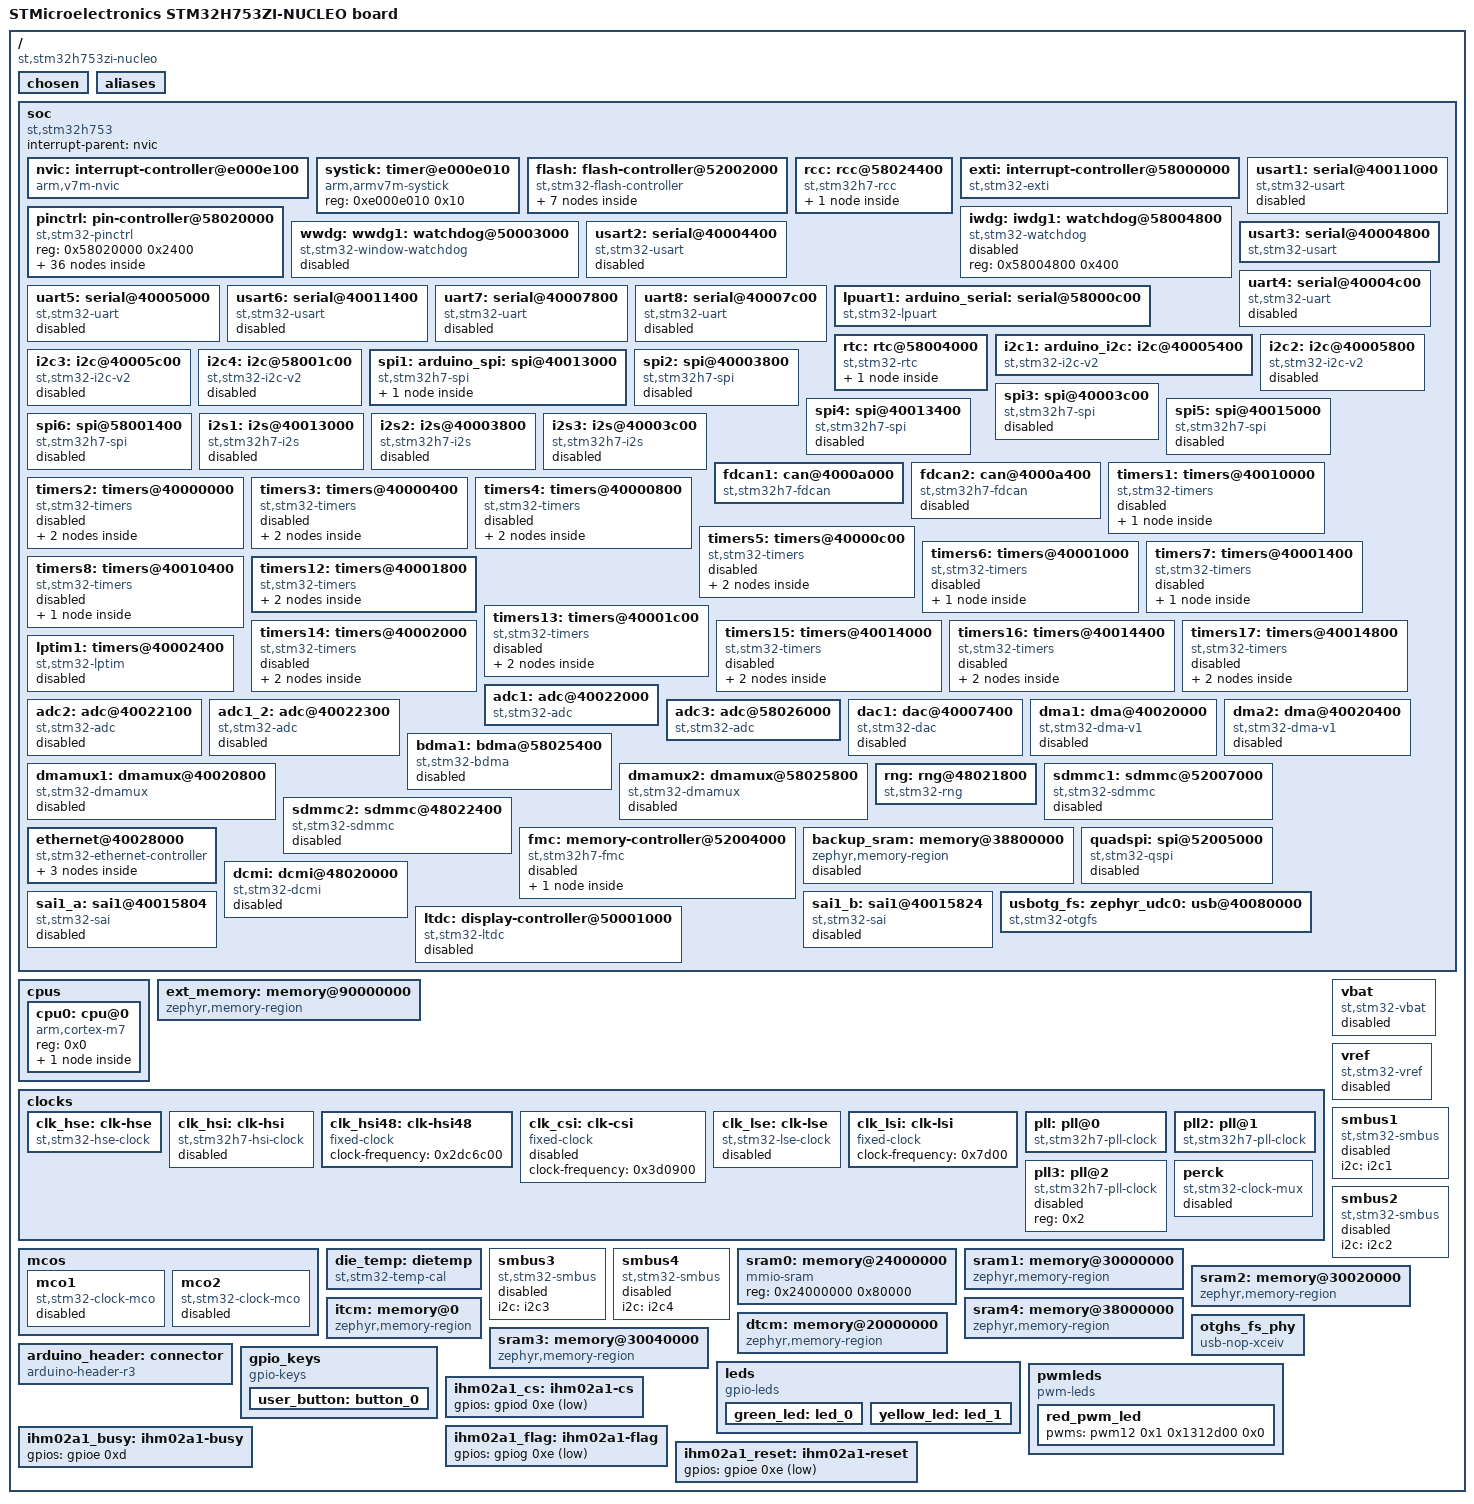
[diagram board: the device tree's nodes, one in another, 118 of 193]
/dts-v1/;

/* node '/' defined in zephyr/dts/common/skeleton.dtsi:9 */
/ {
	#address-cells = < 0x1 >;                              /* in zephyr/dts/common/skeleton.dtsi:10 */
	#size-cells = < 0x1 >;                                 /* in zephyr/dts/common/skeleton.dtsi:11 */
	model = "STMicroelectronics STM32H753ZI-NUCLEO board"; /* in zephyr/boards/st/nucleo_h753zi/nucleo_h753zi.dts:14 */
	compatible = "st,stm32h753zi-nucleo";                  /* in zephyr/boards/st/nucleo_h753zi/nucleo_h753zi.dts:15 */

	/* node '/chosen' defined in zephyr/dts/common/skeleton.dtsi:12 */
	chosen {
		zephyr,entropy = &rng;                    /* in zephyr/dts/arm/st/h7/stm32h7.dtsi:28 */
		zephyr,flash-controller = &flash;         /* in zephyr/dts/arm/st/h7/stm32h7.dtsi:29 */
		zephyr,shell-uart = &usart3;              /* in zephyr/boards/st/nucleo_h753zi/nucleo_h753zi.dts:19 */
		zephyr,sram = &sram0;                     /* in zephyr/boards/st/nucleo_h753zi/nucleo_h753zi.dts:20 */
		zephyr,flash = &flash0;                   /* in zephyr/boards/st/nucleo_h753zi/nucleo_h753zi.dts:21 */
		zephyr,dtcm = &dtcm;                      /* in zephyr/boards/st/nucleo_h753zi/nucleo_h753zi.dts:22 */
		zephyr,code-partition = &slot0_partition; /* in zephyr/boards/st/nucleo_h753zi/nucleo_h753zi.dts:23 */
		zephyr,canbus = &fdcan1;                  /* in zephyr/boards/st/nucleo_h753zi/nucleo_h753zi.dts:24 */
		zephyr,console = &usart3;                 /* in ../apps/stm32h753zi_stepper/boards/shields/x_nucleo_ihm02a1/x_nucleo_ihm02a1.overlay:13 */
	};

	/* node '/aliases' defined in zephyr/dts/common/skeleton.dtsi:13 */
	aliases {
		die-temp0 = &die_temp;   /* in zephyr/boards/st/nucleo_h753zi/nucleo_h753zi.dts:60 */
		led0 = &green_led;       /* in zephyr/boards/st/nucleo_h753zi/nucleo_h753zi.dts:61 */
		led1 = &yellow_led;      /* in zephyr/boards/st/nucleo_h753zi/nucleo_h753zi.dts:62 */
		pwm-led0 = &red_pwm_led; /* in zephyr/boards/st/nucleo_h753zi/nucleo_h753zi.dts:63 */
		sw0 = &user_button;      /* in zephyr/boards/st/nucleo_h753zi/nucleo_h753zi.dts:64 */
		volt-sensor1 = &vbat;    /* in zephyr/boards/st/nucleo_h753zi/nucleo_h753zi.dts:65 */
	};

	/* node '/soc' defined in zephyr/dts/arm/armv7-m.dtsi:6 */
	soc {
		#address-cells = < 0x1 >;     /* in zephyr/dts/arm/armv7-m.dtsi:7 */
		#size-cells = < 0x1 >;        /* in zephyr/dts/arm/armv7-m.dtsi:8 */
		interrupt-parent = < &nvic >; /* in zephyr/dts/arm/armv7-m.dtsi:10 */
		ranges;                       /* in zephyr/dts/arm/armv7-m.dtsi:11 */
		compatible = "st,stm32h753",
		             "st,stm32h7",
		             "simple-bus";    /* in zephyr/dts/arm/st/h7/stm32h753.dtsi:11 */

		/* node '/soc/interrupt-controller@e000e100' defined in zephyr/dts/arm/armv7-m.dtsi:13 */
		nvic: interrupt-controller@e000e100 {
			#address-cells = < 0x1 >;            /* in zephyr/dts/arm/armv7-m.dtsi:14 */
			compatible = "arm,v7m-nvic";         /* in zephyr/dts/arm/armv7-m.dtsi:15 */
			reg = < 0xe000e100 0xc00 >;          /* in zephyr/dts/arm/armv7-m.dtsi:16 */
			interrupt-controller;                /* in zephyr/dts/arm/armv7-m.dtsi:17 */
			#interrupt-cells = < 0x2 >;          /* in zephyr/dts/arm/armv7-m.dtsi:18 */
			arm,num-irq-priority-bits = < 0x4 >; /* in zephyr/dts/arm/st/h7/stm32h7.dtsi:1196 */
			phandle = < 0x1 >;                   /* in zephyr/dts/arm/armv7-m.dtsi:10 */
		};

		/* node '/soc/timer@e000e010' defined in zephyr/dts/arm/armv7-m.dtsi:21 */
		systick: timer@e000e010 {
			compatible = "arm,armv7m-systick"; /* in zephyr/dts/arm/armv7-m.dtsi:22 */
			reg = < 0xe000e010 0x10 >;         /* in zephyr/dts/arm/armv7-m.dtsi:23 */
		};

		/* node '/soc/flash-controller@52002000' defined in zephyr/dts/arm/st/h7/stm32h7.dtsi:145 */
		flash: flash-controller@52002000 {
			compatible = "st,stm32-flash-controller",
			             "st,stm32h7-flash-controller"; /* in zephyr/dts/arm/st/h7/stm32h7.dtsi:146 */
			reg = < 0x52002000 0x400 >;                 /* in zephyr/dts/arm/st/h7/stm32h7.dtsi:147 */
			interrupts = < 0x4 0x0 >;                   /* in zephyr/dts/arm/st/h7/stm32h7.dtsi:148 */
			#address-cells = < 0x1 >;                   /* in zephyr/dts/arm/st/h7/stm32h7.dtsi:150 */
			#size-cells = < 0x1 >;                      /* in zephyr/dts/arm/st/h7/stm32h7.dtsi:151 */

			/* node '/soc/flash-controller@52002000/flash@8000000' defined in zephyr/dts/arm/st/h7/stm32h742.dtsi:15 */
			flash0: flash@8000000 {
				compatible = "st,stm32-nv-flash",
				             "soc-nv-flash";      /* in zephyr/dts/arm/st/h7/stm32h742.dtsi:16 */
				write-block-size = < 0x20 >;      /* in zephyr/dts/arm/st/h7/stm32h742.dtsi:17 */
				erase-block-size = < 0x20000 >;   /* in zephyr/dts/arm/st/h7/stm32h742.dtsi:18 */
				max-erase-time = < 0xfa0 >;       /* in zephyr/dts/arm/st/h7/stm32h742.dtsi:20 */
				reg = < 0x8000000 0x200000 >;     /* in zephyr/dts/arm/st/h7/stm32h753Xi.dtsi:14 */

				/* node '/soc/flash-controller@52002000/flash@8000000/partitions' defined in zephyr/boards/st/nucleo_h753zi/nucleo_h753zi.dts:231 */
				partitions {
					compatible = "fixed-partitions"; /* in zephyr/boards/st/nucleo_h753zi/nucleo_h753zi.dts:232 */
					#address-cells = < 0x1 >;        /* in zephyr/boards/st/nucleo_h753zi/nucleo_h753zi.dts:233 */
					#size-cells = < 0x1 >;           /* in zephyr/boards/st/nucleo_h753zi/nucleo_h753zi.dts:234 */

					/* node '/soc/flash-controller@52002000/flash@8000000/partitions/partition@0' defined in zephyr/boards/st/nucleo_h753zi/nucleo_h753zi.dts:237 */
					boot_partition: partition@0 {
						label = "mcuboot";     /* in zephyr/boards/st/nucleo_h753zi/nucleo_h753zi.dts:238 */
						reg = < 0x0 0x20000 >; /* in zephyr/boards/st/nucleo_h753zi/nucleo_h753zi.dts:239 */
						read-only;             /* in zephyr/boards/st/nucleo_h753zi/nucleo_h753zi.dts:240 */
					};

					/* node '/soc/flash-controller@52002000/flash@8000000/partitions/partition@20000' defined in zephyr/boards/st/nucleo_h753zi/nucleo_h753zi.dts:244 */
					storage_partition: partition@20000 {
						label = "storage";         /* in zephyr/boards/st/nucleo_h753zi/nucleo_h753zi.dts:245 */
						reg = < 0x20000 0x20000 >; /* in zephyr/boards/st/nucleo_h753zi/nucleo_h753zi.dts:246 */
					};

					/* node '/soc/flash-controller@52002000/flash@8000000/partitions/partition@40000' defined in zephyr/boards/st/nucleo_h753zi/nucleo_h753zi.dts:250 */
					slot0_partition: partition@40000 {
						label = "image-0";         /* in zephyr/boards/st/nucleo_h753zi/nucleo_h753zi.dts:251 */
						reg = < 0x40000 0x40000 >; /* in zephyr/boards/st/nucleo_h753zi/nucleo_h753zi.dts:252 */
					};

					/* node '/soc/flash-controller@52002000/flash@8000000/partitions/partition@80000' defined in zephyr/boards/st/nucleo_h753zi/nucleo_h753zi.dts:256 */
					slot1_partition: partition@80000 {
						label = "image-1";         /* in zephyr/boards/st/nucleo_h753zi/nucleo_h753zi.dts:257 */
						reg = < 0x80000 0x40000 >; /* in zephyr/boards/st/nucleo_h753zi/nucleo_h753zi.dts:258 */
					};

					/* node '/soc/flash-controller@52002000/flash@8000000/partitions/partition@c0000' defined in zephyr/boards/st/nucleo_h753zi/nucleo_h753zi.dts:262 */
					scratch_partition: partition@c0000 {
						label = "image-scratch";   /* in zephyr/boards/st/nucleo_h753zi/nucleo_h753zi.dts:263 */
						reg = < 0xc0000 0x20000 >; /* in zephyr/boards/st/nucleo_h753zi/nucleo_h753zi.dts:264 */
					};
				};
			};
		};

		/* node '/soc/rcc@58024400' defined in zephyr/dts/arm/st/h7/stm32h7.dtsi:154 */
		rcc: rcc@58024400 {
			compatible = "st,stm32h7-rcc";    /* in zephyr/dts/arm/st/h7/stm32h7.dtsi:155 */
			#clock-cells = < 0x2 >;           /* in zephyr/dts/arm/st/h7/stm32h7.dtsi:156 */
			reg = < 0x58024400 0x400 >;       /* in zephyr/dts/arm/st/h7/stm32h7.dtsi:157 */
			clocks = < &pll >;                /* in zephyr/boards/st/nucleo_h753zi/nucleo_h753zi.dts:104 */
			clock-frequency = < 0x1c9c3800 >; /* in zephyr/boards/st/nucleo_h753zi/nucleo_h753zi.dts:105 */
			d1cpre = < 0x1 >;                 /* in zephyr/boards/st/nucleo_h753zi/nucleo_h753zi.dts:106 */
			hpre = < 0x2 >;                   /* in zephyr/boards/st/nucleo_h753zi/nucleo_h753zi.dts:107 */
			d1ppre = < 0x2 >;                 /* in zephyr/boards/st/nucleo_h753zi/nucleo_h753zi.dts:108 */
			d2ppre1 = < 0x2 >;                /* in zephyr/boards/st/nucleo_h753zi/nucleo_h753zi.dts:109 */
			d2ppre2 = < 0x2 >;                /* in zephyr/boards/st/nucleo_h753zi/nucleo_h753zi.dts:110 */
			d3ppre = < 0x2 >;                 /* in zephyr/boards/st/nucleo_h753zi/nucleo_h753zi.dts:111 */
			phandle = < 0x3 >;                /* in zephyr/dts/arm/st/h7/stm32h7.dtsi:171 */

			/* node '/soc/rcc@58024400/reset-controller' defined in zephyr/dts/arm/st/h7/stm32h7.dtsi:159 */
			rctl: reset-controller {
				compatible = "st,stm32-rcc-rctl"; /* in zephyr/dts/arm/st/h7/stm32h7.dtsi:160 */
				#reset-cells = < 0x1 >;           /* in zephyr/dts/arm/st/h7/stm32h7.dtsi:161 */
				phandle = < 0x4 >;                /* in zephyr/dts/arm/st/h7/stm32h7.dtsi:294 */
			};
		};

		/* node '/soc/interrupt-controller@58000000' defined in zephyr/dts/arm/st/h7/stm32h7.dtsi:165 */
		exti: interrupt-controller@58000000 {
			compatible = "st,stm32-exti";  /* in zephyr/dts/arm/st/h7/stm32h7.dtsi:166 */
			interrupt-controller;          /* in zephyr/dts/arm/st/h7/stm32h7.dtsi:167 */
			#interrupt-cells = < 0x1 >;    /* in zephyr/dts/arm/st/h7/stm32h7.dtsi:168 */
			#address-cells = < 0x1 >;      /* in zephyr/dts/arm/st/h7/stm32h7.dtsi:169 */
			reg = < 0x58000000 0x400 >;    /* in zephyr/dts/arm/st/h7/stm32h7.dtsi:170 */
			clocks = < &rcc 0xf4 0x2 >;    /* in zephyr/dts/arm/st/h7/stm32h7.dtsi:171 */
			num-lines = < 0x60 >;          /* in zephyr/dts/arm/st/h7/stm32h7.dtsi:172 */
			interrupts = < 0x6 0x0 >,
			             < 0x7 0x0 >,
			             < 0x8 0x0 >,
			             < 0x9 0x0 >,
			             < 0xa 0x0 >,
			             < 0x17 0x0 >,
			             < 0x28 0x0 >;     /* in zephyr/dts/arm/st/h7/stm32h7.dtsi:173 */
			interrupt-names = "line0",
			                  "line1",
			                  "line2",
			                  "line3",
			                  "line4",
			                  "line5-9",
			                  "line10-15"; /* in zephyr/dts/arm/st/h7/stm32h7.dtsi:175 */
			line-ranges = < 0x0 0x1 >,
			              < 0x1 0x1 >,
			              < 0x2 0x1 >,
			              < 0x3 0x1 >,
			              < 0x4 0x1 >,
			              < 0x5 0x5 >,
			              < 0xa 0x6 >;     /* in zephyr/dts/arm/st/h7/stm32h7.dtsi:177 */
		};

		/* node '/soc/pin-controller@58020000' defined in zephyr/dts/arm/st/h7/stm32h7.dtsi:181 */
		pinctrl: pin-controller@58020000 {
			compatible = "st,stm32-pinctrl"; /* in zephyr/dts/arm/st/h7/stm32h7.dtsi:182 */
			#address-cells = < 0x1 >;        /* in zephyr/dts/arm/st/h7/stm32h7.dtsi:183 */
			#size-cells = < 0x1 >;           /* in zephyr/dts/arm/st/h7/stm32h7.dtsi:184 */
			reg = < 0x58020000 0x2400 >;     /* in zephyr/dts/arm/st/h7/stm32h7.dtsi:185 */

			/* node '/soc/pin-controller@58020000/gpio@58020000' defined in zephyr/dts/arm/st/h7/stm32h7.dtsi:187 */
			gpioa: gpio@58020000 {
				compatible = "st,stm32-gpio"; /* in zephyr/dts/arm/st/h7/stm32h7.dtsi:188 */
				gpio-controller;              /* in zephyr/dts/arm/st/h7/stm32h7.dtsi:189 */
				#gpio-cells = < 0x2 >;        /* in zephyr/dts/arm/st/h7/stm32h7.dtsi:190 */
				reg = < 0x58020000 0x400 >;   /* in zephyr/dts/arm/st/h7/stm32h7.dtsi:191 */
				clocks = < &rcc 0xe0 0x1 >;   /* in zephyr/dts/arm/st/h7/stm32h7.dtsi:192 */
				phandle = < 0x29 >;           /* in zephyr/boards/st/nucleo_h753zi/arduino_r3_connector.dtsi:13 */
			};

			/* node '/soc/pin-controller@58020000/gpio@58020400' defined in zephyr/dts/arm/st/h7/stm32h7.dtsi:195 */
			gpiob: gpio@58020400 {
				compatible = "st,stm32-gpio"; /* in zephyr/dts/arm/st/h7/stm32h7.dtsi:196 */
				gpio-controller;              /* in zephyr/dts/arm/st/h7/stm32h7.dtsi:197 */
				#gpio-cells = < 0x2 >;        /* in zephyr/dts/arm/st/h7/stm32h7.dtsi:198 */
				reg = < 0x58020400 0x400 >;   /* in zephyr/dts/arm/st/h7/stm32h7.dtsi:199 */
				clocks = < &rcc 0xe0 0x2 >;   /* in zephyr/dts/arm/st/h7/stm32h7.dtsi:200 */
				phandle = < 0x2b >;           /* in zephyr/boards/st/nucleo_h753zi/arduino_r3_connector.dtsi:13 */
			};

			/* node '/soc/pin-controller@58020000/gpio@58020800' defined in zephyr/dts/arm/st/h7/stm32h7.dtsi:203 */
			gpioc: gpio@58020800 {
				compatible = "st,stm32-gpio"; /* in zephyr/dts/arm/st/h7/stm32h7.dtsi:204 */
				gpio-controller;              /* in zephyr/dts/arm/st/h7/stm32h7.dtsi:205 */
				#gpio-cells = < 0x2 >;        /* in zephyr/dts/arm/st/h7/stm32h7.dtsi:206 */
				reg = < 0x58020800 0x400 >;   /* in zephyr/dts/arm/st/h7/stm32h7.dtsi:207 */
				clocks = < &rcc 0xe0 0x4 >;   /* in zephyr/dts/arm/st/h7/stm32h7.dtsi:208 */
				phandle = < 0x2a >;           /* in zephyr/boards/st/nucleo_h753zi/arduino_r3_connector.dtsi:13 */
			};

			/* node '/soc/pin-controller@58020000/gpio@58020C00' defined in zephyr/dts/arm/st/h7/stm32h7.dtsi:211 */
			gpiod: gpio@58020C00 {
				compatible = "st,stm32-gpio"; /* in zephyr/dts/arm/st/h7/stm32h7.dtsi:212 */
				gpio-controller;              /* in zephyr/dts/arm/st/h7/stm32h7.dtsi:213 */
				#gpio-cells = < 0x2 >;        /* in zephyr/dts/arm/st/h7/stm32h7.dtsi:214 */
				reg = < 0x58020c00 0x400 >;   /* in zephyr/dts/arm/st/h7/stm32h7.dtsi:215 */
				clocks = < &rcc 0xe0 0x8 >;   /* in zephyr/dts/arm/st/h7/stm32h7.dtsi:216 */
				phandle = < 0xe >;            /* in zephyr/boards/st/nucleo_h753zi/nucleo_h753zi.dts:227 */
			};

			/* node '/soc/pin-controller@58020000/gpio@58021000' defined in zephyr/dts/arm/st/h7/stm32h7.dtsi:219 */
			gpioe: gpio@58021000 {
				compatible = "st,stm32-gpio"; /* in zephyr/dts/arm/st/h7/stm32h7.dtsi:220 */
				gpio-controller;              /* in zephyr/dts/arm/st/h7/stm32h7.dtsi:221 */
				#gpio-cells = < 0x2 >;        /* in zephyr/dts/arm/st/h7/stm32h7.dtsi:222 */
				reg = < 0x58021000 0x400 >;   /* in zephyr/dts/arm/st/h7/stm32h7.dtsi:223 */
				clocks = < &rcc 0xe0 0x10 >;  /* in zephyr/dts/arm/st/h7/stm32h7.dtsi:224 */
				phandle = < 0x2e >;           /* in zephyr/boards/st/nucleo_h753zi/arduino_r3_connector.dtsi:13 */
			};

			/* node '/soc/pin-controller@58020000/gpio@58021400' defined in zephyr/dts/arm/st/h7/stm32h7.dtsi:227 */
			gpiof: gpio@58021400 {
				compatible = "st,stm32-gpio"; /* in zephyr/dts/arm/st/h7/stm32h7.dtsi:228 */
				gpio-controller;              /* in zephyr/dts/arm/st/h7/stm32h7.dtsi:229 */
				#gpio-cells = < 0x2 >;        /* in zephyr/dts/arm/st/h7/stm32h7.dtsi:230 */
				reg = < 0x58021400 0x400 >;   /* in zephyr/dts/arm/st/h7/stm32h7.dtsi:231 */
				clocks = < &rcc 0xe0 0x20 >;  /* in zephyr/dts/arm/st/h7/stm32h7.dtsi:232 */
				phandle = < 0x2c >;           /* in zephyr/boards/st/nucleo_h753zi/arduino_r3_connector.dtsi:13 */
			};

			/* node '/soc/pin-controller@58020000/gpio@58021800' defined in zephyr/dts/arm/st/h7/stm32h7.dtsi:235 */
			gpiog: gpio@58021800 {
				compatible = "st,stm32-gpio"; /* in zephyr/dts/arm/st/h7/stm32h7.dtsi:236 */
				gpio-controller;              /* in zephyr/dts/arm/st/h7/stm32h7.dtsi:237 */
				#gpio-cells = < 0x2 >;        /* in zephyr/dts/arm/st/h7/stm32h7.dtsi:238 */
				reg = < 0x58021800 0x400 >;   /* in zephyr/dts/arm/st/h7/stm32h7.dtsi:239 */
				clocks = < &rcc 0xe0 0x40 >;  /* in zephyr/dts/arm/st/h7/stm32h7.dtsi:240 */
				phandle = < 0x2d >;           /* in zephyr/boards/st/nucleo_h753zi/arduino_r3_connector.dtsi:13 */
			};

			/* node '/soc/pin-controller@58020000/gpio@58021C00' defined in zephyr/dts/arm/st/h7/stm32h7.dtsi:243 */
			gpioh: gpio@58021C00 {
				compatible = "st,stm32-gpio"; /* in zephyr/dts/arm/st/h7/stm32h7.dtsi:244 */
				gpio-controller;              /* in zephyr/dts/arm/st/h7/stm32h7.dtsi:245 */
				#gpio-cells = < 0x2 >;        /* in zephyr/dts/arm/st/h7/stm32h7.dtsi:246 */
				reg = < 0x58021c00 0x400 >;   /* in zephyr/dts/arm/st/h7/stm32h7.dtsi:247 */
				clocks = < &rcc 0xe0 0x80 >;  /* in zephyr/dts/arm/st/h7/stm32h7.dtsi:248 */
			};

			/* node '/soc/pin-controller@58020000/gpio@58022000' defined in zephyr/dts/arm/st/h7/stm32h7.dtsi:251 */
			gpioi: gpio@58022000 {
				compatible = "st,stm32-gpio"; /* in zephyr/dts/arm/st/h7/stm32h7.dtsi:252 */
				gpio-controller;              /* in zephyr/dts/arm/st/h7/stm32h7.dtsi:253 */
				#gpio-cells = < 0x2 >;        /* in zephyr/dts/arm/st/h7/stm32h7.dtsi:254 */
				reg = < 0x58022000 0x400 >;   /* in zephyr/dts/arm/st/h7/stm32h7.dtsi:255 */
				clocks = < &rcc 0xe0 0x100 >; /* in zephyr/dts/arm/st/h7/stm32h7.dtsi:256 */
			};

			/* node '/soc/pin-controller@58020000/gpio@58022400' defined in zephyr/dts/arm/st/h7/stm32h7.dtsi:259 */
			gpioj: gpio@58022400 {
				compatible = "st,stm32-gpio"; /* in zephyr/dts/arm/st/h7/stm32h7.dtsi:260 */
				gpio-controller;              /* in zephyr/dts/arm/st/h7/stm32h7.dtsi:261 */
				#gpio-cells = < 0x2 >;        /* in zephyr/dts/arm/st/h7/stm32h7.dtsi:262 */
				reg = < 0x58022400 0x400 >;   /* in zephyr/dts/arm/st/h7/stm32h7.dtsi:263 */
				clocks = < &rcc 0xe0 0x200 >; /* in zephyr/dts/arm/st/h7/stm32h7.dtsi:264 */
			};

			/* node '/soc/pin-controller@58020000/gpio@58022800' defined in zephyr/dts/arm/st/h7/stm32h7.dtsi:267 */
			gpiok: gpio@58022800 {
				compatible = "st,stm32-gpio"; /* in zephyr/dts/arm/st/h7/stm32h7.dtsi:268 */
				gpio-controller;              /* in zephyr/dts/arm/st/h7/stm32h7.dtsi:269 */
				#gpio-cells = < 0x2 >;        /* in zephyr/dts/arm/st/h7/stm32h7.dtsi:270 */
				reg = < 0x58022800 0x400 >;   /* in zephyr/dts/arm/st/h7/stm32h7.dtsi:271 */
				clocks = < &rcc 0xe0 0x400 >; /* in zephyr/dts/arm/st/h7/stm32h7.dtsi:272 */
			};

			/* node '/soc/pin-controller@58020000/adc1_inp15_pa3' defined in modules/hal/stm32/dts/st/h7/stm32h753zitx-pinctrl.dtsi:31 */
			adc1_inp15_pa3: adc1_inp15_pa3 {
				pinmux = < 0x70 >;  /* in modules/hal/stm32/dts/st/h7/stm32h753zitx-pinctrl.dtsi:32 */
				phandle = < 0x13 >; /* in zephyr/boards/st/nucleo_h753zi/nucleo_h753zi.dts:159 */
			};

			/* node '/soc/pin-controller@58020000/adc3_inp5_pf3' defined in modules/hal/stm32/dts/st/h7/stm32h753zitx-pinctrl.dtsi:211 */
			adc3_inp5_pf3: adc3_inp5_pf3 {
				pinmux = < 0xa70 >; /* in modules/hal/stm32/dts/st/h7/stm32h753zitx-pinctrl.dtsi:212 */
				phandle = < 0x14 >; /* in zephyr/boards/st/nucleo_h753zi/nucleo_h753zi.dts:167 */
			};

			/* node '/soc/pin-controller@58020000/eth_ref_clk_pa1' defined in modules/hal/stm32/dts/st/h7/stm32h753zitx-pinctrl.dtsi:1185 */
			eth_ref_clk_pa1: eth_ref_clk_pa1 {
				pinmux = < 0x2b >;             /* in modules/hal/stm32/dts/st/h7/stm32h753zitx-pinctrl.dtsi:1186 */
				slew-rate = "very-high-speed"; /* in modules/hal/stm32/dts/st/h7/stm32h753zitx-pinctrl.dtsi:1187 */
				phandle = < 0x17 >;            /* in zephyr/boards/st/nucleo_h753zi/nucleo_h753zi.dts:200 */
			};

			/* node '/soc/pin-controller@58020000/eth_mdio_pa2' defined in modules/hal/stm32/dts/st/h7/stm32h753zitx-pinctrl.dtsi:1195 */
			eth_mdio_pa2: eth_mdio_pa2 {
				pinmux = < 0x4b >;             /* in modules/hal/stm32/dts/st/h7/stm32h753zitx-pinctrl.dtsi:1196 */
				slew-rate = "very-high-speed"; /* in modules/hal/stm32/dts/st/h7/stm32h753zitx-pinctrl.dtsi:1197 */
				phandle = < 0x1d >;            /* in zephyr/boards/st/nucleo_h753zi/nucleo_h753zi.dts:214 */
			};

			/* node '/soc/pin-controller@58020000/eth_crs_dv_pa7' defined in modules/hal/stm32/dts/st/h7/stm32h753zitx-pinctrl.dtsi:1205 */
			eth_crs_dv_pa7: eth_crs_dv_pa7 {
				pinmux = < 0xeb >;             /* in modules/hal/stm32/dts/st/h7/stm32h753zitx-pinctrl.dtsi:1206 */
				slew-rate = "very-high-speed"; /* in modules/hal/stm32/dts/st/h7/stm32h753zitx-pinctrl.dtsi:1207 */
				phandle = < 0x18 >;            /* in zephyr/boards/st/nucleo_h753zi/nucleo_h753zi.dts:200 */
			};

			/* node '/soc/pin-controller@58020000/eth_txd1_pb13' defined in modules/hal/stm32/dts/st/h7/stm32h753zitx-pinctrl.dtsi:1250 */
			eth_txd1_pb13: eth_txd1_pb13 {
				pinmux = < 0x3ab >;            /* in modules/hal/stm32/dts/st/h7/stm32h753zitx-pinctrl.dtsi:1251 */
				slew-rate = "very-high-speed"; /* in modules/hal/stm32/dts/st/h7/stm32h753zitx-pinctrl.dtsi:1252 */
				phandle = < 0x1b >;            /* in zephyr/boards/st/nucleo_h753zi/nucleo_h753zi.dts:200 */
			};

			/* node '/soc/pin-controller@58020000/eth_mdc_pc1' defined in modules/hal/stm32/dts/st/h7/stm32h753zitx-pinctrl.dtsi:1255 */
			eth_mdc_pc1: eth_mdc_pc1 {
				pinmux = < 0x42b >;            /* in modules/hal/stm32/dts/st/h7/stm32h753zitx-pinctrl.dtsi:1256 */
				slew-rate = "very-high-speed"; /* in modules/hal/stm32/dts/st/h7/stm32h753zitx-pinctrl.dtsi:1257 */
				phandle = < 0x1e >;            /* in zephyr/boards/st/nucleo_h753zi/nucleo_h753zi.dts:214 */
			};

			/* node '/soc/pin-controller@58020000/eth_rxd0_pc4' defined in modules/hal/stm32/dts/st/h7/stm32h753zitx-pinctrl.dtsi:1270 */
			eth_rxd0_pc4: eth_rxd0_pc4 {
				pinmux = < 0x48b >;            /* in modules/hal/stm32/dts/st/h7/stm32h753zitx-pinctrl.dtsi:1271 */
				slew-rate = "very-high-speed"; /* in modules/hal/stm32/dts/st/h7/stm32h753zitx-pinctrl.dtsi:1272 */
				phandle = < 0x15 >;            /* in zephyr/boards/st/nucleo_h753zi/nucleo_h753zi.dts:200 */
			};

			/* node '/soc/pin-controller@58020000/eth_rxd1_pc5' defined in modules/hal/stm32/dts/st/h7/stm32h753zitx-pinctrl.dtsi:1275 */
			eth_rxd1_pc5: eth_rxd1_pc5 {
				pinmux = < 0x4ab >;            /* in modules/hal/stm32/dts/st/h7/stm32h753zitx-pinctrl.dtsi:1276 */
				slew-rate = "very-high-speed"; /* in modules/hal/stm32/dts/st/h7/stm32h753zitx-pinctrl.dtsi:1277 */
				phandle = < 0x16 >;            /* in zephyr/boards/st/nucleo_h753zi/nucleo_h753zi.dts:200 */
			};

			/* node '/soc/pin-controller@58020000/eth_tx_en_pg11' defined in modules/hal/stm32/dts/st/h7/stm32h753zitx-pinctrl.dtsi:1290 */
			eth_tx_en_pg11: eth_tx_en_pg11 {
				pinmux = < 0xd6b >;            /* in modules/hal/stm32/dts/st/h7/stm32h753zitx-pinctrl.dtsi:1291 */
				slew-rate = "very-high-speed"; /* in modules/hal/stm32/dts/st/h7/stm32h753zitx-pinctrl.dtsi:1292 */
				phandle = < 0x19 >;            /* in zephyr/boards/st/nucleo_h753zi/nucleo_h753zi.dts:200 */
			};

			/* node '/soc/pin-controller@58020000/eth_txd0_pg13' defined in modules/hal/stm32/dts/st/h7/stm32h753zitx-pinctrl.dtsi:1300 */
			eth_txd0_pg13: eth_txd0_pg13 {
				pinmux = < 0xdab >;            /* in modules/hal/stm32/dts/st/h7/stm32h753zitx-pinctrl.dtsi:1301 */
				slew-rate = "very-high-speed"; /* in modules/hal/stm32/dts/st/h7/stm32h753zitx-pinctrl.dtsi:1302 */
				phandle = < 0x1a >;            /* in zephyr/boards/st/nucleo_h753zi/nucleo_h753zi.dts:200 */
			};

			/* node '/soc/pin-controller@58020000/fdcan1_rx_pd0' defined in modules/hal/stm32/dts/st/h7/stm32h753zitx-pinctrl.dtsi:1320 */
			fdcan1_rx_pd0: fdcan1_rx_pd0 {
				pinmux = < 0x609 >; /* in modules/hal/stm32/dts/st/h7/stm32h753zitx-pinctrl.dtsi:1321 */
				phandle = < 0x10 >; /* in zephyr/boards/st/nucleo_h753zi/nucleo_h753zi.dts:185 */
			};

			/* node '/soc/pin-controller@58020000/fdcan1_tx_pd1' defined in modules/hal/stm32/dts/st/h7/stm32h753zitx-pinctrl.dtsi:1342 */
			fdcan1_tx_pd1: fdcan1_tx_pd1 {
				pinmux = < 0x629 >; /* in modules/hal/stm32/dts/st/h7/stm32h753zitx-pinctrl.dtsi:1343 */
				phandle = < 0x11 >; /* in zephyr/boards/st/nucleo_h753zi/nucleo_h753zi.dts:185 */
			};

			/* node '/soc/pin-controller@58020000/i2c1_scl_pb8' defined in modules/hal/stm32/dts/st/h7/stm32h753zitx-pinctrl.dtsi:1790 */
			i2c1_scl_pb8: i2c1_scl_pb8 {
				pinmux = < 0x304 >; /* in modules/hal/stm32/dts/st/h7/stm32h753zitx-pinctrl.dtsi:1791 */
				bias-pull-up;       /* in modules/hal/stm32/dts/st/h7/stm32h753zitx-pinctrl.dtsi:1792 */
				drive-open-drain;   /* in modules/hal/stm32/dts/st/h7/stm32h753zitx-pinctrl.dtsi:1793 */
				phandle = < 0x9 >;  /* in zephyr/boards/st/nucleo_h753zi/nucleo_h753zi.dts:141 */
			};

			/* node '/soc/pin-controller@58020000/i2c1_sda_pb9' defined in modules/hal/stm32/dts/st/h7/stm32h753zitx-pinctrl.dtsi:1846 */
			i2c1_sda_pb9: i2c1_sda_pb9 {
				pinmux = < 0x324 >; /* in modules/hal/stm32/dts/st/h7/stm32h753zitx-pinctrl.dtsi:1847 */
				bias-pull-up;       /* in modules/hal/stm32/dts/st/h7/stm32h753zitx-pinctrl.dtsi:1848 */
				drive-open-drain;   /* in modules/hal/stm32/dts/st/h7/stm32h753zitx-pinctrl.dtsi:1849 */
				phandle = < 0xa >;  /* in zephyr/boards/st/nucleo_h753zi/nucleo_h753zi.dts:141 */
			};

			/* node '/soc/pin-controller@58020000/spi1_miso_pa6' defined in modules/hal/stm32/dts/st/h7/stm32h753zitx-pinctrl.dtsi:2836 */
			spi1_miso_pa6: spi1_miso_pa6 {
				pinmux = < 0xc5 >; /* in modules/hal/stm32/dts/st/h7/stm32h753zitx-pinctrl.dtsi:2837 */
				bias-pull-down;    /* in modules/hal/stm32/dts/st/h7/stm32h753zitx-pinctrl.dtsi:2838 */
				phandle = < 0xc >; /* in zephyr/boards/st/nucleo_h753zi/nucleo_h753zi.dts:225 */
			};

			/* node '/soc/pin-controller@58020000/spi1_mosi_pb5' defined in modules/hal/stm32/dts/st/h7/stm32h753zitx-pinctrl.dtsi:2908 */
			spi1_mosi_pb5: spi1_mosi_pb5 {
				pinmux = < 0x2a5 >; /* in modules/hal/stm32/dts/st/h7/stm32h753zitx-pinctrl.dtsi:2909 */
				bias-pull-down;     /* in modules/hal/stm32/dts/st/h7/stm32h753zitx-pinctrl.dtsi:2910 */
				phandle = < 0xd >;  /* in zephyr/boards/st/nucleo_h753zi/nucleo_h753zi.dts:225 */
			};

			/* node '/soc/pin-controller@58020000/spi1_sck_pa5' defined in modules/hal/stm32/dts/st/h7/stm32h753zitx-pinctrl.dtsi:3067 */
			spi1_sck_pa5: spi1_sck_pa5 {
				pinmux = < 0xa5 >;             /* in modules/hal/stm32/dts/st/h7/stm32h753zitx-pinctrl.dtsi:3068 */
				bias-pull-down;                /* in modules/hal/stm32/dts/st/h7/stm32h753zitx-pinctrl.dtsi:3069 */
				slew-rate = "very-high-speed"; /* in modules/hal/stm32/dts/st/h7/stm32h753zitx-pinctrl.dtsi:3070 */
				phandle = < 0xb >;             /* in zephyr/boards/st/nucleo_h753zi/nucleo_h753zi.dts:225 */
			};

			/* node '/soc/pin-controller@58020000/tim12_ch1_pb14' defined in modules/hal/stm32/dts/st/h7/stm32h753zitx-pinctrl.dtsi:3331 */
			tim12_ch1_pb14: tim12_ch1_pb14 {
				pinmux = < 0x3c2 >; /* in modules/hal/stm32/dts/st/h7/stm32h753zitx-pinctrl.dtsi:3332 */
				phandle = < 0x12 >; /* in zephyr/boards/st/nucleo_h753zi/nucleo_h753zi.dts:153 */
			};

			/* node '/soc/pin-controller@58020000/lpuart1_rx_pb7' defined in modules/hal/stm32/dts/st/h7/stm32h753zitx-pinctrl.dtsi:3765 */
			lpuart1_rx_pb7: lpuart1_rx_pb7 {
				pinmux = < 0x2e8 >; /* in modules/hal/stm32/dts/st/h7/stm32h753zitx-pinctrl.dtsi:3766 */
				phandle = < 0x8 >;  /* in zephyr/boards/st/nucleo_h753zi/nucleo_h753zi.dts:115 */
			};

			/* node '/soc/pin-controller@58020000/usart3_rx_pd9' defined in modules/hal/stm32/dts/st/h7/stm32h753zitx-pinctrl.dtsi:3793 */
			usart3_rx_pd9: usart3_rx_pd9 {
				pinmux = < 0x727 >; /* in modules/hal/stm32/dts/st/h7/stm32h753zitx-pinctrl.dtsi:3794 */
				phandle = < 0x6 >;  /* in zephyr/boards/st/nucleo_h753zi/nucleo_h753zi.dts:122 */
			};

			/* node '/soc/pin-controller@58020000/lpuart1_tx_pb6' defined in modules/hal/stm32/dts/st/h7/stm32h753zitx-pinctrl.dtsi:3869 */
			lpuart1_tx_pb6: lpuart1_tx_pb6 {
				pinmux = < 0x2c8 >; /* in modules/hal/stm32/dts/st/h7/stm32h753zitx-pinctrl.dtsi:3870 */
				bias-pull-up;       /* in modules/hal/stm32/dts/st/h7/stm32h753zitx-pinctrl.dtsi:3871 */
				phandle = < 0x7 >;  /* in zephyr/boards/st/nucleo_h753zi/nucleo_h753zi.dts:115 */
			};

			/* node '/soc/pin-controller@58020000/usart3_tx_pd8' defined in modules/hal/stm32/dts/st/h7/stm32h753zitx-pinctrl.dtsi:3904 */
			usart3_tx_pd8: usart3_tx_pd8 {
				pinmux = < 0x707 >; /* in modules/hal/stm32/dts/st/h7/stm32h753zitx-pinctrl.dtsi:3905 */
				bias-pull-up;       /* in modules/hal/stm32/dts/st/h7/stm32h753zitx-pinctrl.dtsi:3906 */
				phandle = < 0x5 >;  /* in zephyr/boards/st/nucleo_h753zi/nucleo_h753zi.dts:122 */
			};

			/* node '/soc/pin-controller@58020000/usb_otg_fs_dm_pa11' defined in modules/hal/stm32/dts/st/h7/stm32h753zitx-pinctrl.dtsi:3998 */
			usb_otg_fs_dm_pa11: usb_otg_fs_dm_pa11 {
				pinmux = < 0x16a >; /* in modules/hal/stm32/dts/st/h7/stm32h753zitx-pinctrl.dtsi:3999 */
				phandle = < 0x21 >; /* in zephyr/boards/st/nucleo_h753zi/nucleo_h753zi.dts:129 */
			};

			/* node '/soc/pin-controller@58020000/usb_otg_fs_dp_pa12' defined in modules/hal/stm32/dts/st/h7/stm32h753zitx-pinctrl.dtsi:4002 */
			usb_otg_fs_dp_pa12: usb_otg_fs_dp_pa12 {
				pinmux = < 0x18a >; /* in modules/hal/stm32/dts/st/h7/stm32h753zitx-pinctrl.dtsi:4003 */
				phandle = < 0x22 >; /* in zephyr/boards/st/nucleo_h753zi/nucleo_h753zi.dts:129 */
			};
		};

		/* node '/soc/watchdog@58004800' defined in zephyr/dts/arm/st/h7/stm32h7.dtsi:276 */
		iwdg: iwdg1: watchdog@58004800 {
			compatible = "st,stm32-watchdog"; /* in zephyr/dts/arm/st/h7/stm32h7.dtsi:277 */
			reg = < 0x58004800 0x400 >;       /* in zephyr/dts/arm/st/h7/stm32h7.dtsi:278 */
			status = "disabled";              /* in zephyr/dts/arm/st/h7/stm32h7.dtsi:279 */
		};

		/* node '/soc/watchdog@50003000' defined in zephyr/dts/arm/st/h7/stm32h7.dtsi:282 */
		wwdg: wwdg1: watchdog@50003000 {
			compatible = "st,stm32-window-watchdog"; /* in zephyr/dts/arm/st/h7/stm32h7.dtsi:283 */
			reg = < 0x50003000 0x1000 >;             /* in zephyr/dts/arm/st/h7/stm32h7.dtsi:284 */
			clocks = < &rcc 0xe4 0x40 >;             /* in zephyr/dts/arm/st/h7/stm32h7.dtsi:285 */
			interrupts = < 0x0 0x7 >;                /* in zephyr/dts/arm/st/h7/stm32h7.dtsi:286 */
			status = "disabled";                     /* in zephyr/dts/arm/st/h7/stm32h7.dtsi:287 */
		};

		/* node '/soc/serial@40011000' defined in zephyr/dts/arm/st/h7/stm32h7.dtsi:290 */
		usart1: serial@40011000 {
			compatible = "st,stm32-usart",
			             "st,stm32-uart";  /* in zephyr/dts/arm/st/h7/stm32h7.dtsi:291 */
			reg = < 0x40011000 0x400 >;    /* in zephyr/dts/arm/st/h7/stm32h7.dtsi:292 */
			clocks = < &rcc 0xf0 0x10 >;   /* in zephyr/dts/arm/st/h7/stm32h7.dtsi:293 */
			resets = < &rctl 0x1304 >;     /* in zephyr/dts/arm/st/h7/stm32h7.dtsi:294 */
			interrupts = < 0x25 0x0 >;     /* in zephyr/dts/arm/st/h7/stm32h7.dtsi:295 */
			status = "disabled";           /* in zephyr/dts/arm/st/h7/stm32h7.dtsi:296 */
		};

		/* node '/soc/serial@40004400' defined in zephyr/dts/arm/st/h7/stm32h7.dtsi:298 */
		usart2: serial@40004400 {
			compatible = "st,stm32-usart",
			             "st,stm32-uart";   /* in zephyr/dts/arm/st/h7/stm32h7.dtsi:299 */
			reg = < 0x40004400 0x400 >;     /* in zephyr/dts/arm/st/h7/stm32h7.dtsi:300 */
			clocks = < &rcc 0xe8 0x20000 >; /* in zephyr/dts/arm/st/h7/stm32h7.dtsi:301 */
			resets = < &rctl 0x1211 >;      /* in zephyr/dts/arm/st/h7/stm32h7.dtsi:302 */
			interrupts = < 0x26 0x0 >;      /* in zephyr/dts/arm/st/h7/stm32h7.dtsi:303 */
			status = "disabled";            /* in zephyr/dts/arm/st/h7/stm32h7.dtsi:304 */
		};

		/* node '/soc/serial@40004800' defined in zephyr/dts/arm/st/h7/stm32h7.dtsi:306 */
		usart3: serial@40004800 {
			compatible = "st,stm32-usart",
			             "st,stm32-uart";                  /* in zephyr/dts/arm/st/h7/stm32h7.dtsi:307 */
			reg = < 0x40004800 0x400 >;                    /* in zephyr/dts/arm/st/h7/stm32h7.dtsi:308 */
			clocks = < &rcc 0xe8 0x40000 >;                /* in zephyr/dts/arm/st/h7/stm32h7.dtsi:309 */
			resets = < &rctl 0x1212 >;                     /* in zephyr/dts/arm/st/h7/stm32h7.dtsi:310 */
			interrupts = < 0x27 0x0 >;                     /* in zephyr/dts/arm/st/h7/stm32h7.dtsi:311 */
			pinctrl-0 = < &usart3_tx_pd8 &usart3_rx_pd9 >; /* in zephyr/boards/st/nucleo_h753zi/nucleo_h753zi.dts:122 */
			pinctrl-names = "default";                     /* in zephyr/boards/st/nucleo_h753zi/nucleo_h753zi.dts:123 */
			current-speed = < 0x1c200 >;                   /* in zephyr/boards/st/nucleo_h753zi/nucleo_h753zi.dts:124 */
			status = "okay";                               /* in zephyr/boards/st/nucleo_h753zi/nucleo_h753zi.dts:125 */
		};

		/* node '/soc/serial@40004c00' defined in zephyr/dts/arm/st/h7/stm32h7.dtsi:314 */
		uart4: serial@40004c00 {
			compatible = "st,stm32-uart";   /* in zephyr/dts/arm/st/h7/stm32h7.dtsi:315 */
			reg = < 0x40004c00 0x400 >;     /* in zephyr/dts/arm/st/h7/stm32h7.dtsi:316 */
			clocks = < &rcc 0xe8 0x80000 >; /* in zephyr/dts/arm/st/h7/stm32h7.dtsi:317 */
			resets = < &rctl 0x1213 >;      /* in zephyr/dts/arm/st/h7/stm32h7.dtsi:318 */
			interrupts = < 0x34 0x0 >;      /* in zephyr/dts/arm/st/h7/stm32h7.dtsi:319 */
			status = "disabled";            /* in zephyr/dts/arm/st/h7/stm32h7.dtsi:320 */
		};

		/* node '/soc/serial@40005000' defined in zephyr/dts/arm/st/h7/stm32h7.dtsi:322 */
		uart5: serial@40005000 {
			compatible = "st,stm32-uart";    /* in zephyr/dts/arm/st/h7/stm32h7.dtsi:323 */
			reg = < 0x40005000 0x400 >;      /* in zephyr/dts/arm/st/h7/stm32h7.dtsi:324 */
			clocks = < &rcc 0xe8 0x100000 >; /* in zephyr/dts/arm/st/h7/stm32h7.dtsi:325 */
			resets = < &rctl 0x1214 >;       /* in zephyr/dts/arm/st/h7/stm32h7.dtsi:326 */
			interrupts = < 0x35 0x0 >;       /* in zephyr/dts/arm/st/h7/stm32h7.dtsi:327 */
			status = "disabled";             /* in zephyr/dts/arm/st/h7/stm32h7.dtsi:328 */
		};

		/* node '/soc/serial@40011400' defined in zephyr/dts/arm/st/h7/stm32h7.dtsi:330 */
		usart6: serial@40011400 {
			compatible = "st,stm32-usart",
			             "st,stm32-uart";  /* in zephyr/dts/arm/st/h7/stm32h7.dtsi:331 */
			reg = < 0x40011400 0x400 >;    /* in zephyr/dts/arm/st/h7/stm32h7.dtsi:332 */
			clocks = < &rcc 0xf0 0x20 >;   /* in zephyr/dts/arm/st/h7/stm32h7.dtsi:333 */
			resets = < &rctl 0x1305 >;     /* in zephyr/dts/arm/st/h7/stm32h7.dtsi:334 */
			interrupts = < 0x47 0x0 >;     /* in zephyr/dts/arm/st/h7/stm32h7.dtsi:335 */
			status = "disabled";           /* in zephyr/dts/arm/st/h7/stm32h7.dtsi:336 */
		};

		/* node '/soc/serial@40007800' defined in zephyr/dts/arm/st/h7/stm32h7.dtsi:338 */
		uart7: serial@40007800 {
			compatible = "st,stm32-uart";      /* in zephyr/dts/arm/st/h7/stm32h7.dtsi:339 */
			reg = < 0x40007800 0x400 >;        /* in zephyr/dts/arm/st/h7/stm32h7.dtsi:340 */
			clocks = < &rcc 0xe8 0x40000000 >; /* in zephyr/dts/arm/st/h7/stm32h7.dtsi:341 */
			resets = < &rctl 0x121e >;         /* in zephyr/dts/arm/st/h7/stm32h7.dtsi:342 */
			interrupts = < 0x52 0x0 >;         /* in zephyr/dts/arm/st/h7/stm32h7.dtsi:343 */
			status = "disabled";               /* in zephyr/dts/arm/st/h7/stm32h7.dtsi:344 */
		};

		/* node '/soc/serial@40007c00' defined in zephyr/dts/arm/st/h7/stm32h7.dtsi:346 */
		uart8: serial@40007c00 {
			compatible = "st,stm32-uart";      /* in zephyr/dts/arm/st/h7/stm32h7.dtsi:347 */
			reg = < 0x40007c00 0x400 >;        /* in zephyr/dts/arm/st/h7/stm32h7.dtsi:348 */
			clocks = < &rcc 0xe8 0x80000000 >; /* in zephyr/dts/arm/st/h7/stm32h7.dtsi:349 */
			resets = < &rctl 0x121f >;         /* in zephyr/dts/arm/st/h7/stm32h7.dtsi:350 */
			interrupts = < 0x53 0x0 >;         /* in zephyr/dts/arm/st/h7/stm32h7.dtsi:351 */
			status = "disabled";               /* in zephyr/dts/arm/st/h7/stm32h7.dtsi:352 */
		};

		/* node '/soc/serial@58000c00' defined in zephyr/dts/arm/st/h7/stm32h7.dtsi:355 */
		lpuart1: arduino_serial: serial@58000c00 {
			compatible = "st,stm32-lpuart",
			             "st,stm32-uart";                    /* in zephyr/dts/arm/st/h7/stm32h7.dtsi:356 */
			reg = < 0x58000c00 0x400 >;                      /* in zephyr/dts/arm/st/h7/stm32h7.dtsi:357 */
			clocks = < &rcc 0xf4 0x8 >;                      /* in zephyr/dts/arm/st/h7/stm32h7.dtsi:358 */
			resets = < &rctl 0x1383 >;                       /* in zephyr/dts/arm/st/h7/stm32h7.dtsi:359 */
			interrupts = < 0x8e 0x0 >;                       /* in zephyr/dts/arm/st/h7/stm32h7.dtsi:360 */
			pinctrl-0 = < &lpuart1_tx_pb6 &lpuart1_rx_pb7 >; /* in zephyr/boards/st/nucleo_h753zi/nucleo_h753zi.dts:115 */
			pinctrl-names = "default";                       /* in zephyr/boards/st/nucleo_h753zi/nucleo_h753zi.dts:116 */
			current-speed = < 0x1c200 >;                     /* in zephyr/boards/st/nucleo_h753zi/nucleo_h753zi.dts:117 */
			status = "okay";                                 /* in zephyr/boards/st/nucleo_h753zi/nucleo_h753zi.dts:118 */
		};

		/* node '/soc/rtc@58004000' defined in zephyr/dts/arm/st/h7/stm32h7.dtsi:364 */
		rtc: rtc@58004000 {
			compatible = "st,stm32-rtc";      /* in zephyr/dts/arm/st/h7/stm32h7.dtsi:365 */
			reg = < 0x58004000 0x400 >;       /* in zephyr/dts/arm/st/h7/stm32h7.dtsi:366 */
			interrupts = < 0x29 0x0 >;        /* in zephyr/dts/arm/st/h7/stm32h7.dtsi:367 */
			prescaler = < 0x8000 >;           /* in zephyr/dts/arm/st/h7/stm32h7.dtsi:369 */
			alarms-count = < 0x2 >;           /* in zephyr/dts/arm/st/h7/stm32h7.dtsi:370 */
			alrm-exti-line = < 0x11 >;        /* in zephyr/dts/arm/st/h7/stm32h7.dtsi:371 */
			clocks = < &rcc 0xf4 0x10000 >,
			         < &rcc 0x3 0x10c80070 >; /* in zephyr/boards/st/nucleo_h753zi/nucleo_h753zi.dts:135 */
			status = "okay";                  /* in zephyr/boards/st/nucleo_h753zi/nucleo_h753zi.dts:137 */

			/* node '/soc/rtc@58004000/backup_regs' defined in zephyr/dts/arm/st/h7/stm32h742.dtsi:57 */
			bbram: backup_regs {
				compatible = "st,stm32-bbram"; /* in zephyr/dts/arm/st/h7/stm32h742.dtsi:58 */
				st,backup-regs = < 0x20 >;     /* in zephyr/dts/arm/st/h7/stm32h742.dtsi:59 */
				status = "disabled";           /* in zephyr/dts/arm/st/h7/stm32h742.dtsi:60 */
			};
		};

		/* node '/soc/i2c@40005400' defined in zephyr/dts/arm/st/h7/stm32h7.dtsi:375 */
		i2c1: arduino_i2c: i2c@40005400 {
			compatible = "st,stm32-i2c-v2";              /* in zephyr/dts/arm/st/h7/stm32h7.dtsi:376 */
			#address-cells = < 0x1 >;                    /* in zephyr/dts/arm/st/h7/stm32h7.dtsi:378 */
			#size-cells = < 0x0 >;                       /* in zephyr/dts/arm/st/h7/stm32h7.dtsi:379 */
			reg = < 0x40005400 0x400 >;                  /* in zephyr/dts/arm/st/h7/stm32h7.dtsi:380 */
			clocks = < &rcc 0xe8 0x200000 >;             /* in zephyr/dts/arm/st/h7/stm32h7.dtsi:381 */
			interrupts = < 0x1f 0x0 >,
			             < 0x20 0x0 >;                   /* in zephyr/dts/arm/st/h7/stm32h7.dtsi:382 */
			interrupt-names = "event",
			                  "error";                   /* in zephyr/dts/arm/st/h7/stm32h7.dtsi:383 */
			pinctrl-0 = < &i2c1_scl_pb8 &i2c1_sda_pb9 >; /* in zephyr/boards/st/nucleo_h753zi/nucleo_h753zi.dts:141 */
			pinctrl-names = "default";                   /* in zephyr/boards/st/nucleo_h753zi/nucleo_h753zi.dts:142 */
			status = "okay";                             /* in zephyr/boards/st/nucleo_h753zi/nucleo_h753zi.dts:143 */
			clock-frequency = < 0x61a80 >;               /* in zephyr/boards/st/nucleo_h753zi/nucleo_h753zi.dts:144 */
			phandle = < 0x25 >;                          /* in zephyr/dts/arm/st/h7/stm32h7.dtsi:1166 */
		};

		/* node '/soc/i2c@40005800' defined in zephyr/dts/arm/st/h7/stm32h7.dtsi:387 */
		i2c2: i2c@40005800 {
			compatible = "st,stm32-i2c-v2";  /* in zephyr/dts/arm/st/h7/stm32h7.dtsi:388 */
			clock-frequency = < 0x186a0 >;   /* in zephyr/dts/arm/st/h7/stm32h7.dtsi:389 */
			#address-cells = < 0x1 >;        /* in zephyr/dts/arm/st/h7/stm32h7.dtsi:390 */
			#size-cells = < 0x0 >;           /* in zephyr/dts/arm/st/h7/stm32h7.dtsi:391 */
			reg = < 0x40005800 0x400 >;      /* in zephyr/dts/arm/st/h7/stm32h7.dtsi:392 */
			clocks = < &rcc 0xe8 0x400000 >; /* in zephyr/dts/arm/st/h7/stm32h7.dtsi:393 */
			interrupts = < 0x21 0x0 >,
			             < 0x22 0x0 >;       /* in zephyr/dts/arm/st/h7/stm32h7.dtsi:394 */
			interrupt-names = "event",
			                  "error";       /* in zephyr/dts/arm/st/h7/stm32h7.dtsi:395 */
			status = "disabled";             /* in zephyr/dts/arm/st/h7/stm32h7.dtsi:396 */
			phandle = < 0x26 >;              /* in zephyr/dts/arm/st/h7/stm32h7.dtsi:1174 */
		};

		/* node '/soc/i2c@40005c00' defined in zephyr/dts/arm/st/h7/stm32h7.dtsi:399 */
		i2c3: i2c@40005c00 {
			compatible = "st,stm32-i2c-v2";  /* in zephyr/dts/arm/st/h7/stm32h7.dtsi:400 */
			clock-frequency = < 0x186a0 >;   /* in zephyr/dts/arm/st/h7/stm32h7.dtsi:401 */
			#address-cells = < 0x1 >;        /* in zephyr/dts/arm/st/h7/stm32h7.dtsi:402 */
			#size-cells = < 0x0 >;           /* in zephyr/dts/arm/st/h7/stm32h7.dtsi:403 */
			reg = < 0x40005c00 0x400 >;      /* in zephyr/dts/arm/st/h7/stm32h7.dtsi:404 */
			clocks = < &rcc 0xe8 0x800000 >; /* in zephyr/dts/arm/st/h7/stm32h7.dtsi:405 */
			interrupts = < 0x48 0x0 >,
			             < 0x49 0x0 >;       /* in zephyr/dts/arm/st/h7/stm32h7.dtsi:406 */
			interrupt-names = "event",
			                  "error";       /* in zephyr/dts/arm/st/h7/stm32h7.dtsi:407 */
			status = "disabled";             /* in zephyr/dts/arm/st/h7/stm32h7.dtsi:408 */
			phandle = < 0x27 >;              /* in zephyr/dts/arm/st/h7/stm32h7.dtsi:1182 */
		};

		/* node '/soc/i2c@58001c00' defined in zephyr/dts/arm/st/h7/stm32h7.dtsi:411 */
		i2c4: i2c@58001c00 {
			compatible = "st,stm32-i2c-v2"; /* in zephyr/dts/arm/st/h7/stm32h7.dtsi:412 */
			clock-frequency = < 0x186a0 >;  /* in zephyr/dts/arm/st/h7/stm32h7.dtsi:413 */
			#address-cells = < 0x1 >;       /* in zephyr/dts/arm/st/h7/stm32h7.dtsi:414 */
			#size-cells = < 0x0 >;          /* in zephyr/dts/arm/st/h7/stm32h7.dtsi:415 */
			reg = < 0x58001c00 0x400 >;     /* in zephyr/dts/arm/st/h7/stm32h7.dtsi:416 */
			clocks = < &rcc 0xf4 0x80 >;    /* in zephyr/dts/arm/st/h7/stm32h7.dtsi:417 */
			interrupts = < 0x5f 0x0 >,
			             < 0x60 0x0 >;      /* in zephyr/dts/arm/st/h7/stm32h7.dtsi:418 */
			interrupt-names = "event",
			                  "error";      /* in zephyr/dts/arm/st/h7/stm32h7.dtsi:419 */
			status = "disabled";            /* in zephyr/dts/arm/st/h7/stm32h7.dtsi:420 */
			phandle = < 0x28 >;             /* in zephyr/dts/arm/st/h7/stm32h7.dtsi:1190 */
		};

		/* node '/soc/spi@40013000' defined in zephyr/dts/arm/st/h7/stm32h7.dtsi:423 */
		spi1: arduino_spi: spi@40013000 {
			compatible = "st,stm32h7-spi",
			             "st,stm32-spi-fifo",
			             "st,stm32-spi";                                 /* in zephyr/dts/arm/st/h7/stm32h7.dtsi:424 */
			#address-cells = < 0x1 >;                                    /* in zephyr/dts/arm/st/h7/stm32h7.dtsi:425 */
			#size-cells = < 0x0 >;                                       /* in zephyr/dts/arm/st/h7/stm32h7.dtsi:426 */
			reg = < 0x40013000 0x400 >;                                  /* in zephyr/dts/arm/st/h7/stm32h7.dtsi:427 */
			clocks = < &rcc 0xf0 0x1000 >,
			         < &rcc 0x9 0x1cc0050 >;                             /* in zephyr/dts/arm/st/h7/stm32h7.dtsi:428 */
			interrupts = < 0x23 0x0 >;                                   /* in zephyr/dts/arm/st/h7/stm32h7.dtsi:430 */
			pinctrl-0 = < &spi1_sck_pa5 &spi1_miso_pa6 &spi1_mosi_pb5 >; /* in zephyr/boards/st/nucleo_h753zi/nucleo_h753zi.dts:225 */
			pinctrl-names = "default";                                   /* in zephyr/boards/st/nucleo_h753zi/nucleo_h753zi.dts:226 */
			cs-gpios = < &gpiod 0xe 0x11 >;                              /* in zephyr/boards/st/nucleo_h753zi/nucleo_h753zi.dts:227 */
			status = "okay";                                             /* in ../apps/stm32h753zi_stepper/boards/shields/x_nucleo_ihm02a1/x_nucleo_ihm02a1.overlay:22 */

			/* node '/soc/spi@40013000/spi-device@0' defined in ../apps/stm32h753zi_stepper/boards/shields/x_nucleo_ihm02a1/x_nucleo_ihm02a1.overlay:23 */
			spidev: spi-device@0 {
				compatible = "zephyr,spidev";      /* in ../apps/stm32h753zi_stepper/boards/shields/x_nucleo_ihm02a1/x_nucleo_ihm02a1.overlay:24 */
				reg = < 0x0 >;                     /* in ../apps/stm32h753zi_stepper/boards/shields/x_nucleo_ihm02a1/x_nucleo_ihm02a1.overlay:25 */
				spi-max-frequency = < 0x1312d00 >; /* in ../apps/stm32h753zi_stepper/boards/shields/x_nucleo_ihm02a1/x_nucleo_ihm02a1.overlay:27 */
				cs-gpios = < &gpiod 0xe 0x1 >;     /* in ../apps/stm32h753zi_stepper/boards/shields/x_nucleo_ihm02a1/x_nucleo_ihm02a1.overlay:29 */
				status = "okay";                   /* in ../apps/stm32h753zi_stepper/boards/shields/x_nucleo_ihm02a1/x_nucleo_ihm02a1.overlay:33 */
			};
		};

		/* node '/soc/spi@40003800' defined in zephyr/dts/arm/st/h7/stm32h7.dtsi:434 */
		spi2: spi@40003800 {
			compatible = "st,stm32h7-spi",
			             "st,stm32-spi-fifo",
			             "st,stm32-spi";      /* in zephyr/dts/arm/st/h7/stm32h7.dtsi:435 */
			#address-cells = < 0x1 >;         /* in zephyr/dts/arm/st/h7/stm32h7.dtsi:436 */
			#size-cells = < 0x0 >;            /* in zephyr/dts/arm/st/h7/stm32h7.dtsi:437 */
			reg = < 0x40003800 0x400 >;       /* in zephyr/dts/arm/st/h7/stm32h7.dtsi:438 */
			clocks = < &rcc 0xe8 0x4000 >,
			         < &rcc 0x9 0x1cc0050 >;  /* in zephyr/dts/arm/st/h7/stm32h7.dtsi:439 */
			interrupts = < 0x24 0x0 >;        /* in zephyr/dts/arm/st/h7/stm32h7.dtsi:441 */
			status = "disabled";              /* in zephyr/dts/arm/st/h7/stm32h7.dtsi:442 */
		};

		/* node '/soc/spi@40003c00' defined in zephyr/dts/arm/st/h7/stm32h7.dtsi:445 */
		spi3: spi@40003c00 {
			compatible = "st,stm32h7-spi",
			             "st,stm32-spi-fifo",
			             "st,stm32-spi";      /* in zephyr/dts/arm/st/h7/stm32h7.dtsi:446 */
			#address-cells = < 0x1 >;         /* in zephyr/dts/arm/st/h7/stm32h7.dtsi:447 */
			#size-cells = < 0x0 >;            /* in zephyr/dts/arm/st/h7/stm32h7.dtsi:448 */
			reg = < 0x40003c00 0x400 >;       /* in zephyr/dts/arm/st/h7/stm32h7.dtsi:449 */
			clocks = < &rcc 0xe8 0x8000 >,
			         < &rcc 0x9 0x1cc0050 >;  /* in zephyr/dts/arm/st/h7/stm32h7.dtsi:450 */
			interrupts = < 0x33 0x0 >;        /* in zephyr/dts/arm/st/h7/stm32h7.dtsi:452 */
			status = "disabled";              /* in zephyr/dts/arm/st/h7/stm32h7.dtsi:453 */
		};

		/* node '/soc/spi@40013400' defined in zephyr/dts/arm/st/h7/stm32h7.dtsi:456 */
		spi4: spi@40013400 {
			compatible = "st,stm32h7-spi",
			             "st,stm32-spi-fifo",
			             "st,stm32-spi";      /* in zephyr/dts/arm/st/h7/stm32h7.dtsi:457 */
			#address-cells = < 0x1 >;         /* in zephyr/dts/arm/st/h7/stm32h7.dtsi:458 */
			#size-cells = < 0x0 >;            /* in zephyr/dts/arm/st/h7/stm32h7.dtsi:459 */
			reg = < 0x40013400 0x400 >;       /* in zephyr/dts/arm/st/h7/stm32h7.dtsi:460 */
			clocks = < &rcc 0xf0 0x2000 >;    /* in zephyr/dts/arm/st/h7/stm32h7.dtsi:461 */
			interrupts = < 0x54 0x0 >;        /* in zephyr/dts/arm/st/h7/stm32h7.dtsi:462 */
			status = "disabled";              /* in zephyr/dts/arm/st/h7/stm32h7.dtsi:463 */
		};

		/* node '/soc/spi@40015000' defined in zephyr/dts/arm/st/h7/stm32h7.dtsi:466 */
		spi5: spi@40015000 {
			compatible = "st,stm32h7-spi",
			             "st,stm32-spi-fifo",
			             "st,stm32-spi";      /* in zephyr/dts/arm/st/h7/stm32h7.dtsi:467 */
			#address-cells = < 0x1 >;         /* in zephyr/dts/arm/st/h7/stm32h7.dtsi:468 */
			#size-cells = < 0x0 >;            /* in zephyr/dts/arm/st/h7/stm32h7.dtsi:469 */
			reg = < 0x40015000 0x400 >;       /* in zephyr/dts/arm/st/h7/stm32h7.dtsi:470 */
			clocks = < &rcc 0xf0 0x100000 >;  /* in zephyr/dts/arm/st/h7/stm32h7.dtsi:471 */
			interrupts = < 0x55 0x0 >;        /* in zephyr/dts/arm/st/h7/stm32h7.dtsi:472 */
			status = "disabled";              /* in zephyr/dts/arm/st/h7/stm32h7.dtsi:473 */
		};

		/* node '/soc/spi@58001400' defined in zephyr/dts/arm/st/h7/stm32h7.dtsi:476 */
		spi6: spi@58001400 {
			compatible = "st,stm32h7-spi",
			             "st,stm32-spi-fifo",
			             "st,stm32-spi";      /* in zephyr/dts/arm/st/h7/stm32h7.dtsi:477 */
			#address-cells = < 0x1 >;         /* in zephyr/dts/arm/st/h7/stm32h7.dtsi:478 */
			#size-cells = < 0x0 >;            /* in zephyr/dts/arm/st/h7/stm32h7.dtsi:479 */
			reg = < 0x58001400 0x400 >;       /* in zephyr/dts/arm/st/h7/stm32h7.dtsi:480 */
			clocks = < &rcc 0xf4 0x20 >;      /* in zephyr/dts/arm/st/h7/stm32h7.dtsi:481 */
			interrupts = < 0x56 0x0 >;        /* in zephyr/dts/arm/st/h7/stm32h7.dtsi:482 */
			status = "disabled";              /* in zephyr/dts/arm/st/h7/stm32h7.dtsi:483 */
		};

		/* node '/soc/i2s@40013000' defined in zephyr/dts/arm/st/h7/stm32h7.dtsi:486 */
		i2s1: i2s@40013000 {
			compatible = "st,stm32h7-i2s",
			             "st,stm32-i2s";                                    /* in zephyr/dts/arm/st/h7/stm32h7.dtsi:487 */
			#address-cells = < 0x1 >;                                       /* in zephyr/dts/arm/st/h7/stm32h7.dtsi:488 */
			#size-cells = < 0x0 >;                                          /* in zephyr/dts/arm/st/h7/stm32h7.dtsi:489 */
			reg = < 0x40013000 0x400 >;                                     /* in zephyr/dts/arm/st/h7/stm32h7.dtsi:490 */
			clocks = < &rcc 0xf0 0x1000 >,
			         < &rcc 0x9 0x1cc0050 >;                                /* in zephyr/dts/arm/st/h7/stm32h7.dtsi:491 */
			dmas = < &dmamux1 0x0 0x26 0x20440 &dmamux1 0x1 0x25 0x20480 >; /* in zephyr/dts/arm/st/h7/stm32h7.dtsi:493 */
			dma-names = "tx",
			            "rx";                                               /* in zephyr/dts/arm/st/h7/stm32h7.dtsi:495 */
			interrupts = < 0x23 0x3 >;                                      /* in zephyr/dts/arm/st/h7/stm32h7.dtsi:496 */
			status = "disabled";                                            /* in zephyr/dts/arm/st/h7/stm32h7.dtsi:497 */
		};

		/* node '/soc/i2s@40003800' defined in zephyr/dts/arm/st/h7/stm32h7.dtsi:500 */
		i2s2: i2s@40003800 {
			compatible = "st,stm32h7-i2s",
			             "st,stm32-i2s";                                    /* in zephyr/dts/arm/st/h7/stm32h7.dtsi:501 */
			#address-cells = < 0x1 >;                                       /* in zephyr/dts/arm/st/h7/stm32h7.dtsi:502 */
			#size-cells = < 0x0 >;                                          /* in zephyr/dts/arm/st/h7/stm32h7.dtsi:503 */
			reg = < 0x40003800 0x400 >;                                     /* in zephyr/dts/arm/st/h7/stm32h7.dtsi:504 */
			clocks = < &rcc 0xe8 0x4000 >,
			         < &rcc 0x9 0x1cc0050 >;                                /* in zephyr/dts/arm/st/h7/stm32h7.dtsi:505 */
			dmas = < &dmamux1 0x0 0x28 0x20440 &dmamux1 0x1 0x27 0x20480 >; /* in zephyr/dts/arm/st/h7/stm32h7.dtsi:507 */
			dma-names = "tx",
			            "rx";                                               /* in zephyr/dts/arm/st/h7/stm32h7.dtsi:509 */
			interrupts = < 0x24 0x0 >;                                      /* in zephyr/dts/arm/st/h7/stm32h7.dtsi:510 */
			status = "disabled";                                            /* in zephyr/dts/arm/st/h7/stm32h7.dtsi:511 */
		};

		/* node '/soc/i2s@40003c00' defined in zephyr/dts/arm/st/h7/stm32h7.dtsi:514 */
		i2s3: i2s@40003c00 {
			compatible = "st,stm32h7-i2s",
			             "st,stm32-i2s";                                    /* in zephyr/dts/arm/st/h7/stm32h7.dtsi:515 */
			#address-cells = < 0x1 >;                                       /* in zephyr/dts/arm/st/h7/stm32h7.dtsi:516 */
			#size-cells = < 0x0 >;                                          /* in zephyr/dts/arm/st/h7/stm32h7.dtsi:517 */
			reg = < 0x40003c00 0x400 >;                                     /* in zephyr/dts/arm/st/h7/stm32h7.dtsi:518 */
			clocks = < &rcc 0xe8 0x8000 >,
			         < &rcc 0x9 0x1cc0050 >;                                /* in zephyr/dts/arm/st/h7/stm32h7.dtsi:519 */
			dmas = < &dmamux1 0x0 0x3e 0x20440 &dmamux1 0x1 0x3d 0x20480 >; /* in zephyr/dts/arm/st/h7/stm32h7.dtsi:521 */
			dma-names = "tx",
			            "rx";                                               /* in zephyr/dts/arm/st/h7/stm32h7.dtsi:523 */
			interrupts = < 0x33 0x0 >;                                      /* in zephyr/dts/arm/st/h7/stm32h7.dtsi:524 */
			status = "disabled";                                            /* in zephyr/dts/arm/st/h7/stm32h7.dtsi:525 */
		};

		/* node '/soc/can@4000a000' defined in zephyr/dts/arm/st/h7/stm32h7.dtsi:528 */
		fdcan1: can@4000a000 {
			compatible = "st,stm32h7-fdcan";                       /* in zephyr/dts/arm/st/h7/stm32h7.dtsi:529 */
			reg = < 0x4000a000 0x400 >,
			      < 0x4000ac00 0x350 >;                            /* in zephyr/dts/arm/st/h7/stm32h7.dtsi:530 */
			reg-names = "m_can",
			            "message_ram";                             /* in zephyr/dts/arm/st/h7/stm32h7.dtsi:531 */
			interrupts = < 0x13 0x0 >,
			             < 0x15 0x0 >,
			             < 0x3f 0x0 >;                             /* in zephyr/dts/arm/st/h7/stm32h7.dtsi:533 */
			interrupt-names = "int0",
			                  "int1",
			                  "calib";                             /* in zephyr/dts/arm/st/h7/stm32h7.dtsi:534 */
			bosch,mram-cfg = < 0x0 0x1c 0x8 0x3 0x3 0x0 0x3 0x3 >; /* in zephyr/dts/arm/st/h7/stm32h7.dtsi:535 */
			clocks = < &rcc 0xec 0x100 >,
			         < &rcc 0xc 0x10dc0050 >;                      /* in zephyr/boards/st/nucleo_h753zi/nucleo_h753zi.dts:183 */
			pinctrl-0 = < &fdcan1_rx_pd0 &fdcan1_tx_pd1 >;         /* in zephyr/boards/st/nucleo_h753zi/nucleo_h753zi.dts:185 */
			pinctrl-names = "default";                             /* in zephyr/boards/st/nucleo_h753zi/nucleo_h753zi.dts:186 */
			status = "okay";                                       /* in zephyr/boards/st/nucleo_h753zi/nucleo_h753zi.dts:187 */
		};

		/* node '/soc/can@4000a400' defined in zephyr/dts/arm/st/h7/stm32h7.dtsi:539 */
		fdcan2: can@4000a400 {
			compatible = "st,stm32h7-fdcan";                         /* in zephyr/dts/arm/st/h7/stm32h7.dtsi:540 */
			reg = < 0x4000a400 0x400 >,
			      < 0x4000ac00 0x6a0 >;                              /* in zephyr/dts/arm/st/h7/stm32h7.dtsi:541 */
			reg-names = "m_can",
			            "message_ram";                               /* in zephyr/dts/arm/st/h7/stm32h7.dtsi:542 */
			clocks = < &rcc 0xec 0x100 >;                            /* in zephyr/dts/arm/st/h7/stm32h7.dtsi:543 */
			interrupts = < 0x14 0x0 >,
			             < 0x16 0x0 >,
			             < 0x3f 0x0 >;                               /* in zephyr/dts/arm/st/h7/stm32h7.dtsi:544 */
			interrupt-names = "int0",
			                  "int1",
			                  "calib";                               /* in zephyr/dts/arm/st/h7/stm32h7.dtsi:545 */
			bosch,mram-cfg = < 0x350 0x1c 0x8 0x3 0x3 0x0 0x3 0x3 >; /* in zephyr/dts/arm/st/h7/stm32h7.dtsi:546 */
			status = "disabled";                                     /* in zephyr/dts/arm/st/h7/stm32h7.dtsi:547 */
		};

		/* node '/soc/timers@40010000' defined in zephyr/dts/arm/st/h7/stm32h7.dtsi:550 */
		timers1: timers@40010000 {
			compatible = "st,stm32-timers"; /* in zephyr/dts/arm/st/h7/stm32h7.dtsi:551 */
			reg = < 0x40010000 0x400 >;     /* in zephyr/dts/arm/st/h7/stm32h7.dtsi:552 */
			clocks = < &rcc 0xf0 0x1 >,
			         < &rcc 0x13 0xff >;    /* in zephyr/dts/arm/st/h7/stm32h7.dtsi:553 */
			resets = < &rctl 0x1300 >;      /* in zephyr/dts/arm/st/h7/stm32h7.dtsi:555 */
			interrupts = < 0x18 0x0 >,
			             < 0x19 0x0 >,
			             < 0x1a 0x0 >,
			             < 0x1b 0x0 >;      /* in zephyr/dts/arm/st/h7/stm32h7.dtsi:556 */
			interrupt-names = "brk",
			                  "up",
			                  "trgcom",
			                  "cc";         /* in zephyr/dts/arm/st/h7/stm32h7.dtsi:557 */
			st,prescaler = < 0x0 >;         /* in zephyr/dts/arm/st/h7/stm32h7.dtsi:558 */
			status = "disabled";            /* in zephyr/dts/arm/st/h7/stm32h7.dtsi:559 */

			/* node '/soc/timers@40010000/pwm' defined in zephyr/dts/arm/st/h7/stm32h7.dtsi:561 */
			pwm {
				compatible = "st,stm32-pwm"; /* in zephyr/dts/arm/st/h7/stm32h7.dtsi:562 */
				status = "disabled";         /* in zephyr/dts/arm/st/h7/stm32h7.dtsi:563 */
				#pwm-cells = < 0x3 >;        /* in zephyr/dts/arm/st/h7/stm32h7.dtsi:564 */
			};
		};

		/* node '/soc/timers@40000000' defined in zephyr/dts/arm/st/h7/stm32h7.dtsi:568 */
		timers2: timers@40000000 {
			compatible = "st,stm32-timers"; /* in zephyr/dts/arm/st/h7/stm32h7.dtsi:569 */
			reg = < 0x40000000 0x400 >;     /* in zephyr/dts/arm/st/h7/stm32h7.dtsi:570 */
			clocks = < &rcc 0xe8 0x1 >,
			         < &rcc 0x12 0xff >;    /* in zephyr/dts/arm/st/h7/stm32h7.dtsi:571 */
			resets = < &rctl 0x1200 >;      /* in zephyr/dts/arm/st/h7/stm32h7.dtsi:573 */
			interrupts = < 0x1c 0x0 >;      /* in zephyr/dts/arm/st/h7/stm32h7.dtsi:574 */
			interrupt-names = "global";     /* in zephyr/dts/arm/st/h7/stm32h7.dtsi:575 */
			st,prescaler = < 0x0 >;         /* in zephyr/dts/arm/st/h7/stm32h7.dtsi:576 */
			status = "disabled";            /* in zephyr/dts/arm/st/h7/stm32h7.dtsi:577 */

			/* node '/soc/timers@40000000/pwm' defined in zephyr/dts/arm/st/h7/stm32h7.dtsi:579 */
			pwm {
				compatible = "st,stm32-pwm"; /* in zephyr/dts/arm/st/h7/stm32h7.dtsi:580 */
				status = "disabled";         /* in zephyr/dts/arm/st/h7/stm32h7.dtsi:581 */
				#pwm-cells = < 0x3 >;        /* in zephyr/dts/arm/st/h7/stm32h7.dtsi:582 */
			};

			/* node '/soc/timers@40000000/counter' defined in zephyr/dts/arm/st/h7/stm32h7.dtsi:585 */
			counter {
				compatible = "st,stm32-counter"; /* in zephyr/dts/arm/st/h7/stm32h7.dtsi:586 */
				status = "disabled";             /* in zephyr/dts/arm/st/h7/stm32h7.dtsi:587 */
			};
		};

		/* node '/soc/timers@40000400' defined in zephyr/dts/arm/st/h7/stm32h7.dtsi:591 */
		timers3: timers@40000400 {
			compatible = "st,stm32-timers"; /* in zephyr/dts/arm/st/h7/stm32h7.dtsi:592 */
			reg = < 0x40000400 0x400 >;     /* in zephyr/dts/arm/st/h7/stm32h7.dtsi:593 */
			clocks = < &rcc 0xe8 0x2 >,
			         < &rcc 0x12 0xff >;    /* in zephyr/dts/arm/st/h7/stm32h7.dtsi:594 */
			resets = < &rctl 0x1201 >;      /* in zephyr/dts/arm/st/h7/stm32h7.dtsi:596 */
			interrupts = < 0x1d 0x0 >;      /* in zephyr/dts/arm/st/h7/stm32h7.dtsi:597 */
			interrupt-names = "global";     /* in zephyr/dts/arm/st/h7/stm32h7.dtsi:598 */
			st,prescaler = < 0x0 >;         /* in zephyr/dts/arm/st/h7/stm32h7.dtsi:599 */
			status = "disabled";            /* in zephyr/dts/arm/st/h7/stm32h7.dtsi:600 */

			/* node '/soc/timers@40000400/pwm' defined in zephyr/dts/arm/st/h7/stm32h7.dtsi:602 */
			pwm {
				compatible = "st,stm32-pwm"; /* in zephyr/dts/arm/st/h7/stm32h7.dtsi:603 */
				status = "disabled";         /* in zephyr/dts/arm/st/h7/stm32h7.dtsi:604 */
				#pwm-cells = < 0x3 >;        /* in zephyr/dts/arm/st/h7/stm32h7.dtsi:605 */
			};

			/* node '/soc/timers@40000400/counter' defined in zephyr/dts/arm/st/h7/stm32h7.dtsi:608 */
			counter {
				compatible = "st,stm32-counter"; /* in zephyr/dts/arm/st/h7/stm32h7.dtsi:609 */
				status = "disabled";             /* in zephyr/dts/arm/st/h7/stm32h7.dtsi:610 */
			};
		};

		/* node '/soc/timers@40000800' defined in zephyr/dts/arm/st/h7/stm32h7.dtsi:614 */
		timers4: timers@40000800 {
			compatible = "st,stm32-timers"; /* in zephyr/dts/arm/st/h7/stm32h7.dtsi:615 */
			reg = < 0x40000800 0x400 >;     /* in zephyr/dts/arm/st/h7/stm32h7.dtsi:616 */
			clocks = < &rcc 0xe8 0x4 >,
			         < &rcc 0x12 0xff >;    /* in zephyr/dts/arm/st/h7/stm32h7.dtsi:617 */
			resets = < &rctl 0x1202 >;      /* in zephyr/dts/arm/st/h7/stm32h7.dtsi:619 */
			interrupts = < 0x1e 0x0 >;      /* in zephyr/dts/arm/st/h7/stm32h7.dtsi:620 */
			interrupt-names = "global";     /* in zephyr/dts/arm/st/h7/stm32h7.dtsi:621 */
			st,prescaler = < 0x0 >;         /* in zephyr/dts/arm/st/h7/stm32h7.dtsi:622 */
			status = "disabled";            /* in zephyr/dts/arm/st/h7/stm32h7.dtsi:623 */

			/* node '/soc/timers@40000800/pwm' defined in zephyr/dts/arm/st/h7/stm32h7.dtsi:625 */
			pwm {
				compatible = "st,stm32-pwm"; /* in zephyr/dts/arm/st/h7/stm32h7.dtsi:626 */
				status = "disabled";         /* in zephyr/dts/arm/st/h7/stm32h7.dtsi:627 */
				#pwm-cells = < 0x3 >;        /* in zephyr/dts/arm/st/h7/stm32h7.dtsi:628 */
			};

			/* node '/soc/timers@40000800/counter' defined in zephyr/dts/arm/st/h7/stm32h7.dtsi:631 */
			counter {
				compatible = "st,stm32-counter"; /* in zephyr/dts/arm/st/h7/stm32h7.dtsi:632 */
				status = "disabled";             /* in zephyr/dts/arm/st/h7/stm32h7.dtsi:633 */
			};
		};

		/* node '/soc/timers@40000c00' defined in zephyr/dts/arm/st/h7/stm32h7.dtsi:637 */
		timers5: timers@40000c00 {
			compatible = "st,stm32-timers"; /* in zephyr/dts/arm/st/h7/stm32h7.dtsi:638 */
			reg = < 0x40000c00 0x400 >;     /* in zephyr/dts/arm/st/h7/stm32h7.dtsi:639 */
			clocks = < &rcc 0xe8 0x8 >,
			         < &rcc 0x12 0xff >;    /* in zephyr/dts/arm/st/h7/stm32h7.dtsi:640 */
			resets = < &rctl 0x1203 >;      /* in zephyr/dts/arm/st/h7/stm32h7.dtsi:642 */
			interrupts = < 0x32 0x0 >;      /* in zephyr/dts/arm/st/h7/stm32h7.dtsi:643 */
			interrupt-names = "global";     /* in zephyr/dts/arm/st/h7/stm32h7.dtsi:644 */
			st,prescaler = < 0x0 >;         /* in zephyr/dts/arm/st/h7/stm32h7.dtsi:645 */
			status = "disabled";            /* in zephyr/dts/arm/st/h7/stm32h7.dtsi:646 */

			/* node '/soc/timers@40000c00/pwm' defined in zephyr/dts/arm/st/h7/stm32h7.dtsi:648 */
			pwm {
				compatible = "st,stm32-pwm"; /* in zephyr/dts/arm/st/h7/stm32h7.dtsi:649 */
				status = "disabled";         /* in zephyr/dts/arm/st/h7/stm32h7.dtsi:650 */
				#pwm-cells = < 0x3 >;        /* in zephyr/dts/arm/st/h7/stm32h7.dtsi:651 */
			};

			/* node '/soc/timers@40000c00/counter' defined in zephyr/dts/arm/st/h7/stm32h7.dtsi:654 */
			counter {
				compatible = "st,stm32-counter"; /* in zephyr/dts/arm/st/h7/stm32h7.dtsi:655 */
				status = "disabled";             /* in zephyr/dts/arm/st/h7/stm32h7.dtsi:656 */
			};
		};

		/* node '/soc/timers@40001000' defined in zephyr/dts/arm/st/h7/stm32h7.dtsi:660 */
		timers6: timers@40001000 {
			compatible = "st,stm32-timers"; /* in zephyr/dts/arm/st/h7/stm32h7.dtsi:661 */
			reg = < 0x40001000 0x400 >;     /* in zephyr/dts/arm/st/h7/stm32h7.dtsi:662 */
			clocks = < &rcc 0xe8 0x10 >,
			         < &rcc 0x12 0xff >;    /* in zephyr/dts/arm/st/h7/stm32h7.dtsi:663 */
			resets = < &rctl 0x1204 >;      /* in zephyr/dts/arm/st/h7/stm32h7.dtsi:665 */
			interrupts = < 0x36 0x0 >;      /* in zephyr/dts/arm/st/h7/stm32h7.dtsi:666 */
			interrupt-names = "global";     /* in zephyr/dts/arm/st/h7/stm32h7.dtsi:667 */
			st,prescaler = < 0x0 >;         /* in zephyr/dts/arm/st/h7/stm32h7.dtsi:668 */
			status = "disabled";            /* in zephyr/dts/arm/st/h7/stm32h7.dtsi:669 */

			/* node '/soc/timers@40001000/counter' defined in zephyr/dts/arm/st/h7/stm32h7.dtsi:671 */
			counter {
				compatible = "st,stm32-counter"; /* in zephyr/dts/arm/st/h7/stm32h7.dtsi:672 */
				status = "disabled";             /* in zephyr/dts/arm/st/h7/stm32h7.dtsi:673 */
			};
		};

		/* node '/soc/timers@40001400' defined in zephyr/dts/arm/st/h7/stm32h7.dtsi:677 */
		timers7: timers@40001400 {
			compatible = "st,stm32-timers"; /* in zephyr/dts/arm/st/h7/stm32h7.dtsi:678 */
			reg = < 0x40001400 0x400 >;     /* in zephyr/dts/arm/st/h7/stm32h7.dtsi:679 */
			clocks = < &rcc 0xe8 0x20 >,
			         < &rcc 0x12 0xff >;    /* in zephyr/dts/arm/st/h7/stm32h7.dtsi:680 */
			resets = < &rctl 0x1205 >;      /* in zephyr/dts/arm/st/h7/stm32h7.dtsi:682 */
			interrupts = < 0x37 0x0 >;      /* in zephyr/dts/arm/st/h7/stm32h7.dtsi:683 */
			interrupt-names = "global";     /* in zephyr/dts/arm/st/h7/stm32h7.dtsi:684 */
			st,prescaler = < 0x0 >;         /* in zephyr/dts/arm/st/h7/stm32h7.dtsi:685 */
			status = "disabled";            /* in zephyr/dts/arm/st/h7/stm32h7.dtsi:686 */

			/* node '/soc/timers@40001400/counter' defined in zephyr/dts/arm/st/h7/stm32h7.dtsi:688 */
			counter {
				compatible = "st,stm32-counter"; /* in zephyr/dts/arm/st/h7/stm32h7.dtsi:689 */
				status = "disabled";             /* in zephyr/dts/arm/st/h7/stm32h7.dtsi:690 */
			};
		};

		/* node '/soc/timers@40010400' defined in zephyr/dts/arm/st/h7/stm32h7.dtsi:694 */
		timers8: timers@40010400 {
			compatible = "st,stm32-timers"; /* in zephyr/dts/arm/st/h7/stm32h7.dtsi:695 */
			reg = < 0x40010400 0x400 >;     /* in zephyr/dts/arm/st/h7/stm32h7.dtsi:696 */
			clocks = < &rcc 0xf0 0x2 >,
			         < &rcc 0x13 0xff >;    /* in zephyr/dts/arm/st/h7/stm32h7.dtsi:697 */
			resets = < &rctl 0x1301 >;      /* in zephyr/dts/arm/st/h7/stm32h7.dtsi:699 */
			interrupts = < 0x2b 0x0 >,
			             < 0x2c 0x0 >,
			             < 0x2d 0x0 >,
			             < 0x2e 0x0 >;      /* in zephyr/dts/arm/st/h7/stm32h7.dtsi:700 */
			interrupt-names = "brk",
			                  "up",
			                  "trgcom",
			                  "cc";         /* in zephyr/dts/arm/st/h7/stm32h7.dtsi:701 */
			st,prescaler = < 0x0 >;         /* in zephyr/dts/arm/st/h7/stm32h7.dtsi:702 */
			status = "disabled";            /* in zephyr/dts/arm/st/h7/stm32h7.dtsi:703 */

			/* node '/soc/timers@40010400/pwm' defined in zephyr/dts/arm/st/h7/stm32h7.dtsi:705 */
			pwm {
				compatible = "st,stm32-pwm"; /* in zephyr/dts/arm/st/h7/stm32h7.dtsi:706 */
				status = "disabled";         /* in zephyr/dts/arm/st/h7/stm32h7.dtsi:707 */
				#pwm-cells = < 0x3 >;        /* in zephyr/dts/arm/st/h7/stm32h7.dtsi:708 */
			};
		};

		/* node '/soc/timers@40001800' defined in zephyr/dts/arm/st/h7/stm32h7.dtsi:712 */
		timers12: timers@40001800 {
			compatible = "st,stm32-timers"; /* in zephyr/dts/arm/st/h7/stm32h7.dtsi:713 */
			reg = < 0x40001800 0x400 >;     /* in zephyr/dts/arm/st/h7/stm32h7.dtsi:714 */
			clocks = < &rcc 0xe8 0x40 >,
			         < &rcc 0x12 0xff >;    /* in zephyr/dts/arm/st/h7/stm32h7.dtsi:715 */
			resets = < &rctl 0x1206 >;      /* in zephyr/dts/arm/st/h7/stm32h7.dtsi:717 */
			interrupts = < 0x2b 0x0 >;      /* in zephyr/dts/arm/st/h7/stm32h7.dtsi:718 */
			interrupt-names = "global";     /* in zephyr/dts/arm/st/h7/stm32h7.dtsi:719 */
			st,prescaler = < 0x2710 >;      /* in zephyr/boards/st/nucleo_h753zi/nucleo_h753zi.dts:148 */
			status = "okay";                /* in zephyr/boards/st/nucleo_h753zi/nucleo_h753zi.dts:149 */

			/* node '/soc/timers@40001800/pwm' defined in zephyr/dts/arm/st/h7/stm32h7.dtsi:723 */
			pwm12: pwm {
				compatible = "st,stm32-pwm";     /* in zephyr/dts/arm/st/h7/stm32h7.dtsi:724 */
				#pwm-cells = < 0x3 >;            /* in zephyr/dts/arm/st/h7/stm32h7.dtsi:726 */
				status = "okay";                 /* in zephyr/boards/st/nucleo_h753zi/nucleo_h753zi.dts:152 */
				pinctrl-0 = < &tim12_ch1_pb14 >; /* in zephyr/boards/st/nucleo_h753zi/nucleo_h753zi.dts:153 */
				pinctrl-names = "default";       /* in zephyr/boards/st/nucleo_h753zi/nucleo_h753zi.dts:154 */
				phandle = < 0x2f >;              /* in zephyr/boards/st/nucleo_h753zi/nucleo_h753zi.dts:45 */
			};

			/* node '/soc/timers@40001800/counter' defined in zephyr/dts/arm/st/h7/stm32h7.dtsi:729 */
			counter {
				compatible = "st,stm32-counter"; /* in zephyr/dts/arm/st/h7/stm32h7.dtsi:730 */
				status = "disabled";             /* in zephyr/dts/arm/st/h7/stm32h7.dtsi:731 */
			};
		};

		/* node '/soc/timers@40001c00' defined in zephyr/dts/arm/st/h7/stm32h7.dtsi:735 */
		timers13: timers@40001c00 {
			compatible = "st,stm32-timers"; /* in zephyr/dts/arm/st/h7/stm32h7.dtsi:736 */
			reg = < 0x40001c00 0x400 >;     /* in zephyr/dts/arm/st/h7/stm32h7.dtsi:737 */
			clocks = < &rcc 0xe8 0x80 >,
			         < &rcc 0x12 0xff >;    /* in zephyr/dts/arm/st/h7/stm32h7.dtsi:738 */
			resets = < &rctl 0x1207 >;      /* in zephyr/dts/arm/st/h7/stm32h7.dtsi:740 */
			interrupts = < 0x2c 0x0 >;      /* in zephyr/dts/arm/st/h7/stm32h7.dtsi:741 */
			interrupt-names = "global";     /* in zephyr/dts/arm/st/h7/stm32h7.dtsi:742 */
			st,prescaler = < 0x0 >;         /* in zephyr/dts/arm/st/h7/stm32h7.dtsi:743 */
			status = "disabled";            /* in zephyr/dts/arm/st/h7/stm32h7.dtsi:744 */

			/* node '/soc/timers@40001c00/pwm' defined in zephyr/dts/arm/st/h7/stm32h7.dtsi:746 */
			pwm {
				compatible = "st,stm32-pwm"; /* in zephyr/dts/arm/st/h7/stm32h7.dtsi:747 */
				status = "disabled";         /* in zephyr/dts/arm/st/h7/stm32h7.dtsi:748 */
				#pwm-cells = < 0x3 >;        /* in zephyr/dts/arm/st/h7/stm32h7.dtsi:749 */
			};

			/* node '/soc/timers@40001c00/counter' defined in zephyr/dts/arm/st/h7/stm32h7.dtsi:752 */
			counter {
				compatible = "st,stm32-counter"; /* in zephyr/dts/arm/st/h7/stm32h7.dtsi:753 */
				status = "disabled";             /* in zephyr/dts/arm/st/h7/stm32h7.dtsi:754 */
			};
		};

		/* node '/soc/timers@40002000' defined in zephyr/dts/arm/st/h7/stm32h7.dtsi:758 */
		timers14: timers@40002000 {
			compatible = "st,stm32-timers"; /* in zephyr/dts/arm/st/h7/stm32h7.dtsi:759 */
			reg = < 0x40002000 0x400 >;     /* in zephyr/dts/arm/st/h7/stm32h7.dtsi:760 */
			clocks = < &rcc 0xe8 0x100 >,
			         < &rcc 0x12 0xff >;    /* in zephyr/dts/arm/st/h7/stm32h7.dtsi:761 */
			resets = < &rctl 0x1208 >;      /* in zephyr/dts/arm/st/h7/stm32h7.dtsi:763 */
			interrupts = < 0x2d 0x0 >;      /* in zephyr/dts/arm/st/h7/stm32h7.dtsi:764 */
			interrupt-names = "global";     /* in zephyr/dts/arm/st/h7/stm32h7.dtsi:765 */
			st,prescaler = < 0x0 >;         /* in zephyr/dts/arm/st/h7/stm32h7.dtsi:766 */
			status = "disabled";            /* in zephyr/dts/arm/st/h7/stm32h7.dtsi:767 */

			/* node '/soc/timers@40002000/pwm' defined in zephyr/dts/arm/st/h7/stm32h7.dtsi:769 */
			pwm {
				compatible = "st,stm32-pwm"; /* in zephyr/dts/arm/st/h7/stm32h7.dtsi:770 */
				status = "disabled";         /* in zephyr/dts/arm/st/h7/stm32h7.dtsi:771 */
				#pwm-cells = < 0x3 >;        /* in zephyr/dts/arm/st/h7/stm32h7.dtsi:772 */
			};

			/* node '/soc/timers@40002000/counter' defined in zephyr/dts/arm/st/h7/stm32h7.dtsi:775 */
			counter {
				compatible = "st,stm32-counter"; /* in zephyr/dts/arm/st/h7/stm32h7.dtsi:776 */
				status = "disabled";             /* in zephyr/dts/arm/st/h7/stm32h7.dtsi:777 */
			};
		};

		/* node '/soc/timers@40014000' defined in zephyr/dts/arm/st/h7/stm32h7.dtsi:781 */
		timers15: timers@40014000 {
			compatible = "st,stm32-timers"; /* in zephyr/dts/arm/st/h7/stm32h7.dtsi:782 */
			reg = < 0x40014000 0x400 >;     /* in zephyr/dts/arm/st/h7/stm32h7.dtsi:783 */
			clocks = < &rcc 0xf0 0x10000 >,
			         < &rcc 0x13 0xff >;    /* in zephyr/dts/arm/st/h7/stm32h7.dtsi:784 */
			resets = < &rctl 0x1310 >;      /* in zephyr/dts/arm/st/h7/stm32h7.dtsi:786 */
			interrupts = < 0x74 0x0 >;      /* in zephyr/dts/arm/st/h7/stm32h7.dtsi:787 */
			interrupt-names = "global";     /* in zephyr/dts/arm/st/h7/stm32h7.dtsi:788 */
			st,prescaler = < 0x0 >;         /* in zephyr/dts/arm/st/h7/stm32h7.dtsi:789 */
			status = "disabled";            /* in zephyr/dts/arm/st/h7/stm32h7.dtsi:790 */

			/* node '/soc/timers@40014000/pwm' defined in zephyr/dts/arm/st/h7/stm32h7.dtsi:792 */
			pwm {
				compatible = "st,stm32-pwm"; /* in zephyr/dts/arm/st/h7/stm32h7.dtsi:793 */
				status = "disabled";         /* in zephyr/dts/arm/st/h7/stm32h7.dtsi:794 */
				#pwm-cells = < 0x3 >;        /* in zephyr/dts/arm/st/h7/stm32h7.dtsi:795 */
			};

			/* node '/soc/timers@40014000/counter' defined in zephyr/dts/arm/st/h7/stm32h7.dtsi:798 */
			counter {
				compatible = "st,stm32-counter"; /* in zephyr/dts/arm/st/h7/stm32h7.dtsi:799 */
				status = "disabled";             /* in zephyr/dts/arm/st/h7/stm32h7.dtsi:800 */
			};
		};

		/* node '/soc/timers@40014400' defined in zephyr/dts/arm/st/h7/stm32h7.dtsi:804 */
		timers16: timers@40014400 {
			compatible = "st,stm32-timers"; /* in zephyr/dts/arm/st/h7/stm32h7.dtsi:805 */
			reg = < 0x40014400 0x400 >;     /* in zephyr/dts/arm/st/h7/stm32h7.dtsi:806 */
			clocks = < &rcc 0xf0 0x20000 >,
			         < &rcc 0x13 0xff >;    /* in zephyr/dts/arm/st/h7/stm32h7.dtsi:807 */
			resets = < &rctl 0x1311 >;      /* in zephyr/dts/arm/st/h7/stm32h7.dtsi:809 */
			interrupts = < 0x75 0x0 >;      /* in zephyr/dts/arm/st/h7/stm32h7.dtsi:810 */
			interrupt-names = "global";     /* in zephyr/dts/arm/st/h7/stm32h7.dtsi:811 */
			st,prescaler = < 0x0 >;         /* in zephyr/dts/arm/st/h7/stm32h7.dtsi:812 */
			status = "disabled";            /* in zephyr/dts/arm/st/h7/stm32h7.dtsi:813 */

			/* node '/soc/timers@40014400/pwm' defined in zephyr/dts/arm/st/h7/stm32h7.dtsi:815 */
			pwm {
				compatible = "st,stm32-pwm"; /* in zephyr/dts/arm/st/h7/stm32h7.dtsi:816 */
				status = "disabled";         /* in zephyr/dts/arm/st/h7/stm32h7.dtsi:817 */
				#pwm-cells = < 0x3 >;        /* in zephyr/dts/arm/st/h7/stm32h7.dtsi:818 */
			};

			/* node '/soc/timers@40014400/counter' defined in zephyr/dts/arm/st/h7/stm32h7.dtsi:821 */
			counter {
				compatible = "st,stm32-counter"; /* in zephyr/dts/arm/st/h7/stm32h7.dtsi:822 */
				status = "disabled";             /* in zephyr/dts/arm/st/h7/stm32h7.dtsi:823 */
			};
		};

		/* node '/soc/timers@40014800' defined in zephyr/dts/arm/st/h7/stm32h7.dtsi:827 */
		timers17: timers@40014800 {
			compatible = "st,stm32-timers"; /* in zephyr/dts/arm/st/h7/stm32h7.dtsi:828 */
			reg = < 0x40014800 0x400 >;     /* in zephyr/dts/arm/st/h7/stm32h7.dtsi:829 */
			clocks = < &rcc 0xf0 0x40000 >,
			         < &rcc 0x13 0xff >;    /* in zephyr/dts/arm/st/h7/stm32h7.dtsi:830 */
			resets = < &rctl 0x1312 >;      /* in zephyr/dts/arm/st/h7/stm32h7.dtsi:832 */
			interrupts = < 0x76 0x0 >;      /* in zephyr/dts/arm/st/h7/stm32h7.dtsi:833 */
			interrupt-names = "global";     /* in zephyr/dts/arm/st/h7/stm32h7.dtsi:834 */
			st,prescaler = < 0x0 >;         /* in zephyr/dts/arm/st/h7/stm32h7.dtsi:835 */
			status = "disabled";            /* in zephyr/dts/arm/st/h7/stm32h7.dtsi:836 */

			/* node '/soc/timers@40014800/pwm' defined in zephyr/dts/arm/st/h7/stm32h7.dtsi:838 */
			pwm {
				compatible = "st,stm32-pwm"; /* in zephyr/dts/arm/st/h7/stm32h7.dtsi:839 */
				status = "disabled";         /* in zephyr/dts/arm/st/h7/stm32h7.dtsi:840 */
				#pwm-cells = < 0x3 >;        /* in zephyr/dts/arm/st/h7/stm32h7.dtsi:841 */
			};

			/* node '/soc/timers@40014800/counter' defined in zephyr/dts/arm/st/h7/stm32h7.dtsi:844 */
			counter {
				compatible = "st,stm32-counter"; /* in zephyr/dts/arm/st/h7/stm32h7.dtsi:845 */
				status = "disabled";             /* in zephyr/dts/arm/st/h7/stm32h7.dtsi:846 */
			};
		};

		/* node '/soc/timers@40002400' defined in zephyr/dts/arm/st/h7/stm32h7.dtsi:850 */
		lptim1: timers@40002400 {
			compatible = "st,stm32-lptim"; /* in zephyr/dts/arm/st/h7/stm32h7.dtsi:851 */
			clocks = < &rcc 0xe8 0x200 >;  /* in zephyr/dts/arm/st/h7/stm32h7.dtsi:852 */
			#address-cells = < 0x1 >;      /* in zephyr/dts/arm/st/h7/stm32h7.dtsi:853 */
			#size-cells = < 0x0 >;         /* in zephyr/dts/arm/st/h7/stm32h7.dtsi:854 */
			reg = < 0x40002400 0x400 >;    /* in zephyr/dts/arm/st/h7/stm32h7.dtsi:855 */
			interrupts = < 0x5d 0x1 >;     /* in zephyr/dts/arm/st/h7/stm32h7.dtsi:856 */
			interrupt-names = "wakeup";    /* in zephyr/dts/arm/st/h7/stm32h7.dtsi:857 */
			status = "disabled";           /* in zephyr/dts/arm/st/h7/stm32h7.dtsi:858 */
		};

		/* node '/soc/adc@40022000' defined in zephyr/dts/arm/st/h7/stm32h7.dtsi:868 */
		adc1: adc@40022000 {
			compatible = "st,stm32-adc";                                    /* in zephyr/dts/arm/st/h7/stm32h7.dtsi:869 */
			reg = < 0x40022000 0x400 >;                                     /* in zephyr/dts/arm/st/h7/stm32h7.dtsi:870 */
			clocks = < &rcc 0xd8 0x20 >;                                    /* in zephyr/dts/arm/st/h7/stm32h7.dtsi:871 */
			interrupts = < 0x12 0x0 >;                                      /* in zephyr/dts/arm/st/h7/stm32h7.dtsi:872 */
			#io-channel-cells = < 0x1 >;                                    /* in zephyr/dts/arm/st/h7/stm32h7.dtsi:874 */
			resolutions = < 0x80e20c 0x75e20c 0x66e20c 0x53e20c 0x47e20c >; /* in zephyr/dts/arm/st/h7/stm32h7.dtsi:875 */
			sampling-times = < 0x2 0x3 0x9 0x11 0x21 0x41 0x184 0x32b >;    /* in zephyr/dts/arm/st/h7/stm32h7.dtsi:880 */
			st,adc-sequencer = "FULLY_CONFIGURABLE";                        /* in zephyr/dts/arm/st/h7/stm32h7.dtsi:881 */
			st,adc-oversampler = "OVERSAMPLER_EXTENDED";                    /* in zephyr/dts/arm/st/h7/stm32h7.dtsi:882 */
			pinctrl-0 = < &adc1_inp15_pa3 >;                                /* in zephyr/boards/st/nucleo_h753zi/nucleo_h753zi.dts:159 */
			pinctrl-names = "default";                                      /* in zephyr/boards/st/nucleo_h753zi/nucleo_h753zi.dts:160 */
			st,adc-clock-source = "SYNC";                                   /* in zephyr/boards/st/nucleo_h753zi/nucleo_h753zi.dts:161 */
			st,adc-prescaler = < 0x4 >;                                     /* in zephyr/boards/st/nucleo_h753zi/nucleo_h753zi.dts:162 */
			status = "okay";                                                /* in zephyr/boards/st/nucleo_h753zi/nucleo_h753zi.dts:163 */
		};

		/* node '/soc/adc@40022100' defined in zephyr/dts/arm/st/h7/stm32h7.dtsi:885 */
		adc2: adc@40022100 {
			compatible = "st,stm32-adc";                                    /* in zephyr/dts/arm/st/h7/stm32h7.dtsi:886 */
			reg = < 0x40022100 0x400 >;                                     /* in zephyr/dts/arm/st/h7/stm32h7.dtsi:887 */
			clocks = < &rcc 0xd8 0x20 >;                                    /* in zephyr/dts/arm/st/h7/stm32h7.dtsi:888 */
			interrupts = < 0x12 0x0 >;                                      /* in zephyr/dts/arm/st/h7/stm32h7.dtsi:889 */
			status = "disabled";                                            /* in zephyr/dts/arm/st/h7/stm32h7.dtsi:890 */
			#io-channel-cells = < 0x1 >;                                    /* in zephyr/dts/arm/st/h7/stm32h7.dtsi:891 */
			resolutions = < 0x80e20c 0x75e20c 0x66e20c 0x53e20c 0x47e20c >; /* in zephyr/dts/arm/st/h7/stm32h7.dtsi:892 */
			sampling-times = < 0x2 0x3 0x9 0x11 0x21 0x41 0x184 0x32b >;    /* in zephyr/dts/arm/st/h7/stm32h7.dtsi:897 */
			st,adc-sequencer = "FULLY_CONFIGURABLE";                        /* in zephyr/dts/arm/st/h7/stm32h7.dtsi:898 */
			st,adc-oversampler = "OVERSAMPLER_EXTENDED";                    /* in zephyr/dts/arm/st/h7/stm32h7.dtsi:899 */
		};

		/* node '/soc/adc@40022300' defined in zephyr/dts/arm/st/h7/stm32h7.dtsi:903 */
		adc1_2: adc@40022300 {
			compatible = "st,stm32-adc";                                    /* in zephyr/dts/arm/st/h7/stm32h7.dtsi:904 */
			reg = < 0x40022300 0x400 >;                                     /* in zephyr/dts/arm/st/h7/stm32h7.dtsi:905 */
			clocks = < &rcc 0xd8 0x20 >;                                    /* in zephyr/dts/arm/st/h7/stm32h7.dtsi:906 */
			interrupts = < 0x12 0x0 >;                                      /* in zephyr/dts/arm/st/h7/stm32h7.dtsi:907 */
			status = "disabled";                                            /* in zephyr/dts/arm/st/h7/stm32h7.dtsi:908 */
			#io-channel-cells = < 0x1 >;                                    /* in zephyr/dts/arm/st/h7/stm32h7.dtsi:909 */
			resolutions = < 0x80e20c 0x75e20c 0x66e20c 0x53e20c 0x47e20c >; /* in zephyr/dts/arm/st/h7/stm32h7.dtsi:910 */
			sampling-times = < 0x2 0x3 0x9 0x11 0x21 0x41 0x184 0x32b >;    /* in zephyr/dts/arm/st/h7/stm32h7.dtsi:915 */
			st,adc-sequencer = "FULLY_CONFIGURABLE";                        /* in zephyr/dts/arm/st/h7/stm32h7.dtsi:916 */
			st,adc-oversampler = "OVERSAMPLER_EXTENDED";                    /* in zephyr/dts/arm/st/h7/stm32h7.dtsi:917 */
		};

		/* node '/soc/adc@58026000' defined in zephyr/dts/arm/st/h7/stm32h7.dtsi:920 */
		adc3: adc@58026000 {
			compatible = "st,stm32-adc";                                    /* in zephyr/dts/arm/st/h7/stm32h7.dtsi:921 */
			reg = < 0x58026000 0x400 >;                                     /* in zephyr/dts/arm/st/h7/stm32h7.dtsi:922 */
			clocks = < &rcc 0xe0 0x1000000 >;                               /* in zephyr/dts/arm/st/h7/stm32h7.dtsi:923 */
			interrupts = < 0x7f 0x0 >;                                      /* in zephyr/dts/arm/st/h7/stm32h7.dtsi:924 */
			#io-channel-cells = < 0x1 >;                                    /* in zephyr/dts/arm/st/h7/stm32h7.dtsi:926 */
			resolutions = < 0x80e20c 0x75e20c 0x66e20c 0x53e20c 0x47e20c >; /* in zephyr/dts/arm/st/h7/stm32h7.dtsi:927 */
			sampling-times = < 0x2 0x3 0x9 0x11 0x21 0x41 0x184 0x32b >;    /* in zephyr/dts/arm/st/h7/stm32h7.dtsi:932 */
			st,adc-sequencer = "FULLY_CONFIGURABLE";                        /* in zephyr/dts/arm/st/h7/stm32h7.dtsi:933 */
			st,adc-oversampler = "OVERSAMPLER_EXTENDED";                    /* in zephyr/dts/arm/st/h7/stm32h7.dtsi:934 */
			pinctrl-0 = < &adc3_inp5_pf3 >;                                 /* in zephyr/boards/st/nucleo_h753zi/nucleo_h753zi.dts:167 */
			pinctrl-names = "default";                                      /* in zephyr/boards/st/nucleo_h753zi/nucleo_h753zi.dts:168 */
			st,adc-clock-source = "SYNC";                                   /* in zephyr/boards/st/nucleo_h753zi/nucleo_h753zi.dts:169 */
			st,adc-prescaler = < 0x4 >;                                     /* in zephyr/boards/st/nucleo_h753zi/nucleo_h753zi.dts:170 */
			status = "okay";                                                /* in zephyr/boards/st/nucleo_h753zi/nucleo_h753zi.dts:171 */
			phandle = < 0x24 >;                                             /* in zephyr/dts/arm/st/h7/stm32h7.dtsi:1144 */
		};

		/* node '/soc/dac@40007400' defined in zephyr/dts/arm/st/h7/stm32h7.dtsi:937 */
		dac1: dac@40007400 {
			compatible = "st,stm32-dac";       /* in zephyr/dts/arm/st/h7/stm32h7.dtsi:938 */
			reg = < 0x40007400 0x400 >;        /* in zephyr/dts/arm/st/h7/stm32h7.dtsi:939 */
			clocks = < &rcc 0xe8 0x20000000 >; /* in zephyr/dts/arm/st/h7/stm32h7.dtsi:940 */
			status = "disabled";               /* in zephyr/dts/arm/st/h7/stm32h7.dtsi:941 */
			#io-channel-cells = < 0x1 >;       /* in zephyr/dts/arm/st/h7/stm32h7.dtsi:942 */
		};

		/* node '/soc/dma@40020000' defined in zephyr/dts/arm/st/h7/stm32h7.dtsi:945 */
		dma1: dma@40020000 {
			compatible = "st,stm32-dma-v1"; /* in zephyr/dts/arm/st/h7/stm32h7.dtsi:946 */
			#dma-cells = < 0x4 >;           /* in zephyr/dts/arm/st/h7/stm32h7.dtsi:947 */
			reg = < 0x40020000 0x400 >;     /* in zephyr/dts/arm/st/h7/stm32h7.dtsi:948 */
			interrupts = < 0xb 0x0 >,
			             < 0xc 0x0 >,
			             < 0xd 0x0 >,
			             < 0xe 0x0 >,
			             < 0xf 0x0 >,
			             < 0x10 0x0 >,
			             < 0x11 0x0 >,
			             < 0x2f 0x0 >;      /* in zephyr/dts/arm/st/h7/stm32h7.dtsi:949 */
			clocks = < &rcc 0xd8 0x1 >;     /* in zephyr/dts/arm/st/h7/stm32h7.dtsi:951 */
			st,mem2mem;                     /* in zephyr/dts/arm/st/h7/stm32h7.dtsi:952 */
			dma-offset = < 0x0 >;           /* in zephyr/dts/arm/st/h7/stm32h7.dtsi:953 */
			dma-requests = < 0x8 >;         /* in zephyr/dts/arm/st/h7/stm32h7.dtsi:954 */
			status = "disabled";            /* in zephyr/dts/arm/st/h7/stm32h7.dtsi:955 */
			phandle = < 0x1f >;             /* in zephyr/dts/arm/st/h7/stm32h7.dtsi:1105 */
		};

		/* node '/soc/dma@40020400' defined in zephyr/dts/arm/st/h7/stm32h7.dtsi:958 */
		dma2: dma@40020400 {
			compatible = "st,stm32-dma-v1"; /* in zephyr/dts/arm/st/h7/stm32h7.dtsi:959 */
			#dma-cells = < 0x4 >;           /* in zephyr/dts/arm/st/h7/stm32h7.dtsi:960 */
			reg = < 0x40020400 0x400 >;     /* in zephyr/dts/arm/st/h7/stm32h7.dtsi:961 */
			interrupts = < 0x38 0x0 >,
			             < 0x39 0x0 >,
			             < 0x3a 0x0 >,
			             < 0x3b 0x0 >,
			             < 0x3c 0x0 >,
			             < 0x44 0x0 >,
			             < 0x45 0x0 >,
			             < 0x46 0x0 >;      /* in zephyr/dts/arm/st/h7/stm32h7.dtsi:962 */
			clocks = < &rcc 0xd8 0x2 >;     /* in zephyr/dts/arm/st/h7/stm32h7.dtsi:964 */
			st,mem2mem;                     /* in zephyr/dts/arm/st/h7/stm32h7.dtsi:965 */
			dma-offset = < 0x8 >;           /* in zephyr/dts/arm/st/h7/stm32h7.dtsi:966 */
			dma-requests = < 0x8 >;         /* in zephyr/dts/arm/st/h7/stm32h7.dtsi:967 */
			status = "disabled";            /* in zephyr/dts/arm/st/h7/stm32h7.dtsi:968 */
		};

		/* node '/soc/bdma@58025400' defined in zephyr/dts/arm/st/h7/stm32h7.dtsi:971 */
		bdma1: bdma@58025400 {
			compatible = "st,stm32-bdma";    /* in zephyr/dts/arm/st/h7/stm32h7.dtsi:972 */
			#dma-cells = < 0x4 >;            /* in zephyr/dts/arm/st/h7/stm32h7.dtsi:973 */
			reg = < 0x58025400 0x400 >;      /* in zephyr/dts/arm/st/h7/stm32h7.dtsi:974 */
			interrupts = < 0x81 0x0 >,
			             < 0x82 0x0 >,
			             < 0x83 0x0 >,
			             < 0x84 0x0 >,
			             < 0x85 0x0 >,
			             < 0x86 0x0 >,
			             < 0x87 0x0 >,
			             < 0x88 0x0 >;       /* in zephyr/dts/arm/st/h7/stm32h7.dtsi:975 */
			clocks = < &rcc 0xe0 0x200000 >; /* in zephyr/dts/arm/st/h7/stm32h7.dtsi:977 */
			st,mem2mem;                      /* in zephyr/dts/arm/st/h7/stm32h7.dtsi:978 */
			dma-offset = < 0x0 >;            /* in zephyr/dts/arm/st/h7/stm32h7.dtsi:979 */
			dma-requests = < 0x8 >;          /* in zephyr/dts/arm/st/h7/stm32h7.dtsi:980 */
			status = "disabled";             /* in zephyr/dts/arm/st/h7/stm32h7.dtsi:981 */
		};

		/* node '/soc/dmamux@40020800' defined in zephyr/dts/arm/st/h7/stm32h7.dtsi:984 */
		dmamux1: dmamux@40020800 {
			compatible = "st,stm32-dmamux"; /* in zephyr/dts/arm/st/h7/stm32h7.dtsi:985 */
			#dma-cells = < 0x3 >;           /* in zephyr/dts/arm/st/h7/stm32h7.dtsi:986 */
			reg = < 0x40020800 0x400 >;     /* in zephyr/dts/arm/st/h7/stm32h7.dtsi:987 */
			interrupts = < 0x66 0x0 >;      /* in zephyr/dts/arm/st/h7/stm32h7.dtsi:988 */
			clocks = < &rcc 0xd8 0x1 >;     /* in zephyr/dts/arm/st/h7/stm32h7.dtsi:990 */
			dma-channels = < 0x10 >;        /* in zephyr/dts/arm/st/h7/stm32h7.dtsi:991 */
			dma-generators = < 0x8 >;       /* in zephyr/dts/arm/st/h7/stm32h7.dtsi:992 */
			status = "disabled";            /* in zephyr/dts/arm/st/h7/stm32h7.dtsi:993 */
			dma-requests = < 0x6b >;        /* in zephyr/dts/arm/st/h7/stm32h742.dtsi:25 */
			phandle = < 0xf >;              /* in zephyr/dts/arm/st/h7/stm32h7.dtsi:493 */
		};

		/* node '/soc/dmamux@58025800' defined in zephyr/dts/arm/st/h7/stm32h7.dtsi:1000 */
		dmamux2: dmamux@58025800 {
			compatible = "st,stm32-dmamux";  /* in zephyr/dts/arm/st/h7/stm32h7.dtsi:1001 */
			#dma-cells = < 0x3 >;            /* in zephyr/dts/arm/st/h7/stm32h7.dtsi:1002 */
			reg = < 0x58025800 0x400 >;      /* in zephyr/dts/arm/st/h7/stm32h7.dtsi:1003 */
			interrupts = < 0x80 0x0 >;       /* in zephyr/dts/arm/st/h7/stm32h7.dtsi:1004 */
			clocks = < &rcc 0xe0 0x200000 >; /* in zephyr/dts/arm/st/h7/stm32h7.dtsi:1006 */
			dma-channels = < 0x8 >;          /* in zephyr/dts/arm/st/h7/stm32h7.dtsi:1007 */
			dma-generators = < 0x8 >;        /* in zephyr/dts/arm/st/h7/stm32h7.dtsi:1008 */
			status = "disabled";             /* in zephyr/dts/arm/st/h7/stm32h7.dtsi:1009 */
			dma-requests = < 0xc >;          /* in zephyr/dts/arm/st/h7/stm32h742.dtsi:29 */
		};

		/* node '/soc/rng@48021800' defined in zephyr/dts/arm/st/h7/stm32h7.dtsi:1016 */
		rng: rng@48021800 {
			compatible = "st,stm32-rng"; /* in zephyr/dts/arm/st/h7/stm32h7.dtsi:1017 */
			reg = < 0x48021800 0x400 >;  /* in zephyr/dts/arm/st/h7/stm32h7.dtsi:1018 */
			clocks = < &rcc 0xdc 0x40 >; /* in zephyr/dts/arm/st/h7/stm32h7.dtsi:1019 */
			interrupts = < 0x50 0x0 >;   /* in zephyr/dts/arm/st/h7/stm32h7.dtsi:1020 */
			status = "okay";             /* in zephyr/boards/st/nucleo_h753zi/nucleo_h753zi.dts:179 */
		};

		/* node '/soc/sdmmc@52007000' defined in zephyr/dts/arm/st/h7/stm32h7.dtsi:1024 */
		sdmmc1: sdmmc@52007000 {
			compatible = "st,stm32-sdmmc";  /* in zephyr/dts/arm/st/h7/stm32h7.dtsi:1025 */
			reg = < 0x52007000 0x400 >;     /* in zephyr/dts/arm/st/h7/stm32h7.dtsi:1026 */
			clocks = < &rcc 0xd4 0x10000 >,
			         < &rcc 0x9 0x50004c >; /* in zephyr/dts/arm/st/h7/stm32h7.dtsi:1027 */
			resets = < &rctl 0xf90 >;       /* in zephyr/dts/arm/st/h7/stm32h7.dtsi:1029 */
			interrupts = < 0x31 0x0 >;      /* in zephyr/dts/arm/st/h7/stm32h7.dtsi:1030 */
			status = "disabled";            /* in zephyr/dts/arm/st/h7/stm32h7.dtsi:1031 */
		};

		/* node '/soc/sdmmc@48022400' defined in zephyr/dts/arm/st/h7/stm32h7.dtsi:1034 */
		sdmmc2: sdmmc@48022400 {
			compatible = "st,stm32-sdmmc";  /* in zephyr/dts/arm/st/h7/stm32h7.dtsi:1035 */
			reg = < 0x48022400 0x400 >;     /* in zephyr/dts/arm/st/h7/stm32h7.dtsi:1036 */
			clocks = < &rcc 0xdc 0x200 >,
			         < &rcc 0x9 0x50004c >; /* in zephyr/dts/arm/st/h7/stm32h7.dtsi:1037 */
			resets = < &rctl 0x1089 >;      /* in zephyr/dts/arm/st/h7/stm32h7.dtsi:1039 */
			interrupts = < 0x7c 0x0 >;      /* in zephyr/dts/arm/st/h7/stm32h7.dtsi:1040 */
			status = "disabled";            /* in zephyr/dts/arm/st/h7/stm32h7.dtsi:1041 */
		};

		/* node '/soc/ethernet@40028000' defined in zephyr/dts/arm/st/h7/stm32h7.dtsi:1044 */
		ethernet@40028000 {
			reg = < 0x40028000 0x8000 >;                 /* in zephyr/dts/arm/st/h7/stm32h7.dtsi:1045 */
			compatible = "st,stm32-ethernet-controller"; /* in zephyr/dts/arm/st/h7/stm32h7.dtsi:1046 */
			clock-names = "stm-eth";                     /* in zephyr/dts/arm/st/h7/stm32h7.dtsi:1047 */
			clocks = < &rcc 0xd8 0x8000 >;               /* in zephyr/dts/arm/st/h7/stm32h7.dtsi:1048 */

			/* node '/soc/ethernet@40028000/ethernet' defined in zephyr/dts/arm/st/h7/stm32h7.dtsi:1050 */
			mac: ethernet {
				compatible = "st,stm32h7-ethernet",
				             "st,stm32-ethernet";                                                                         /* in zephyr/dts/arm/st/h7/stm32h7.dtsi:1051 */
				interrupts = < 0x3d 0x0 >;                                                                                /* in zephyr/dts/arm/st/h7/stm32h7.dtsi:1052 */
				clock-names = "mac-clk-tx",
				              "mac-clk-rx";                                                                               /* in zephyr/dts/arm/st/h7/stm32h7.dtsi:1053 */
				clocks = < &rcc 0xd8 0x10000 >,
				         < &rcc 0xd8 0x20000 >;                                                                           /* in zephyr/dts/arm/st/h7/stm32h7.dtsi:1054 */
				status = "okay";                                                                                          /* in zephyr/boards/st/nucleo_h753zi/nucleo_h753zi.dts:199 */
				pinctrl-0 = < &eth_rxd0_pc4 &eth_rxd1_pc5 &eth_ref_clk_pa1 &eth_crs_dv_pa7 &eth_tx_en_pg11 &eth_txd0_pg13
				              &eth_txd1_pb13 >;                                                                           /* in zephyr/boards/st/nucleo_h753zi/nucleo_h753zi.dts:200 */
				pinctrl-names = "default";                                                                                /* in zephyr/boards/st/nucleo_h753zi/nucleo_h753zi.dts:207 */
				phy-connection-type = "rmii";                                                                             /* in zephyr/boards/st/nucleo_h753zi/nucleo_h753zi.dts:208 */
				phy-handle = < &eth_phy >;                                                                                /* in zephyr/boards/st/nucleo_h753zi/nucleo_h753zi.dts:209 */
			};

			/* node '/soc/ethernet@40028000/mdio' defined in zephyr/dts/arm/st/h7/stm32h7.dtsi:1059 */
			mdio: mdio {
				compatible = "st,stm32-mdio";               /* in zephyr/dts/arm/st/h7/stm32h7.dtsi:1060 */
				#address-cells = < 0x1 >;                   /* in zephyr/dts/arm/st/h7/stm32h7.dtsi:1061 */
				#size-cells = < 0x0 >;                      /* in zephyr/dts/arm/st/h7/stm32h7.dtsi:1062 */
				status = "okay";                            /* in zephyr/boards/st/nucleo_h753zi/nucleo_h753zi.dts:213 */
				pinctrl-0 = < &eth_mdio_pa2 &eth_mdc_pc1 >; /* in zephyr/boards/st/nucleo_h753zi/nucleo_h753zi.dts:214 */
				pinctrl-names = "default";                  /* in zephyr/boards/st/nucleo_h753zi/nucleo_h753zi.dts:215 */

				/* node '/soc/ethernet@40028000/mdio/ethernet-phy@0' defined in zephyr/boards/st/nucleo_h753zi/nucleo_h753zi.dts:217 */
				eth_phy: ethernet-phy@0 {
					compatible = "ethernet-phy"; /* in zephyr/boards/st/nucleo_h753zi/nucleo_h753zi.dts:218 */
					reg = < 0x0 >;               /* in zephyr/boards/st/nucleo_h753zi/nucleo_h753zi.dts:219 */
					phandle = < 0x1c >;          /* in zephyr/boards/st/nucleo_h753zi/nucleo_h753zi.dts:209 */
				};
			};
		};

		/* node '/soc/memory-controller@52004000' defined in zephyr/dts/arm/st/h7/stm32h7.dtsi:1067 */
		fmc: memory-controller@52004000 {
			compatible = "st,stm32h7-fmc"; /* in zephyr/dts/arm/st/h7/stm32h7.dtsi:1068 */
			reg = < 0x52004000 0x400 >;    /* in zephyr/dts/arm/st/h7/stm32h7.dtsi:1069 */
			clocks = < &rcc 0xd4 0x1000 >; /* in zephyr/dts/arm/st/h7/stm32h7.dtsi:1070 */
			status = "disabled";           /* in zephyr/dts/arm/st/h7/stm32h7.dtsi:1071 */

			/* node '/soc/memory-controller@52004000/sdram' defined in zephyr/dts/arm/st/h7/stm32h7.dtsi:1073 */
			sdram: sdram {
				compatible = "st,stm32-fmc-sdram"; /* in zephyr/dts/arm/st/h7/stm32h7.dtsi:1074 */
				#address-cells = < 0x1 >;          /* in zephyr/dts/arm/st/h7/stm32h7.dtsi:1075 */
				#size-cells = < 0x0 >;             /* in zephyr/dts/arm/st/h7/stm32h7.dtsi:1076 */
				status = "disabled";               /* in zephyr/dts/arm/st/h7/stm32h7.dtsi:1077 */
			};
		};

		/* node '/soc/memory@38800000' defined in zephyr/dts/arm/st/h7/stm32h7.dtsi:1081 */
		backup_sram: memory@38800000 {
			compatible = "zephyr,memory-region",
			             "st,stm32-backup-sram";  /* in zephyr/dts/arm/st/h7/stm32h7.dtsi:1082 */
			reg = < 0x38800000 0x1000 >;          /* in zephyr/dts/arm/st/h7/stm32h7.dtsi:1083 */
			clocks = < &rcc 0xe0 0x10000000 >;    /* in zephyr/dts/arm/st/h7/stm32h7.dtsi:1084 */
			zephyr,memory-region = "BACKUP_SRAM"; /* in zephyr/dts/arm/st/h7/stm32h7.dtsi:1085 */
			status = "disabled";                  /* in zephyr/dts/arm/st/h7/stm32h7.dtsi:1086 */
		};

		/* node '/soc/spi@52005000' defined in zephyr/dts/arm/st/h7/stm32h7.dtsi:1089 */
		quadspi: spi@52005000 {
			compatible = "st,stm32-qspi";    /* in zephyr/dts/arm/st/h7/stm32h7.dtsi:1090 */
			#address-cells = < 0x1 >;        /* in zephyr/dts/arm/st/h7/stm32h7.dtsi:1091 */
			#size-cells = < 0x0 >;           /* in zephyr/dts/arm/st/h7/stm32h7.dtsi:1092 */
			reg = < 0x52005000 0x1000 >,
			      < 0x90000000 0x10000000 >; /* in zephyr/dts/arm/st/h7/stm32h7.dtsi:1093 */
			interrupts = < 0x5c 0x0 >;       /* in zephyr/dts/arm/st/h7/stm32h7.dtsi:1094 */
			clocks = < &rcc 0xd4 0x4000 >;   /* in zephyr/dts/arm/st/h7/stm32h7.dtsi:1095 */
			status = "disabled";             /* in zephyr/dts/arm/st/h7/stm32h7.dtsi:1096 */
		};

		/* node '/soc/dcmi@48020000' defined in zephyr/dts/arm/st/h7/stm32h7.dtsi:1099 */
		dcmi: dcmi@48020000 {
			compatible = "st,stm32-dcmi";          /* in zephyr/dts/arm/st/h7/stm32h7.dtsi:1100 */
			reg = < 0x48020000 0x400 >;            /* in zephyr/dts/arm/st/h7/stm32h7.dtsi:1101 */
			interrupts = < 0x4e 0x0 >;             /* in zephyr/dts/arm/st/h7/stm32h7.dtsi:1102 */
			interrupt-names = "dcmi";              /* in zephyr/dts/arm/st/h7/stm32h7.dtsi:1103 */
			clocks = < &rcc 0xdc 0x1 >;            /* in zephyr/dts/arm/st/h7/stm32h7.dtsi:1104 */
			dmas = < &dma1 0x0 0x4b 0x24480 0x0 >; /* in zephyr/dts/arm/st/h7/stm32h7.dtsi:1105 */
			status = "disabled";                   /* in zephyr/dts/arm/st/h7/stm32h7.dtsi:1108 */
		};

		/* node '/soc/sai1@40015804' defined in zephyr/dts/arm/st/h7/stm32h7.dtsi:1111 */
		sai1_a: sai1@40015804 {
			compatible = "st,stm32-sai";           /* in zephyr/dts/arm/st/h7/stm32h7.dtsi:1112 */
			#address-cells = < 0x1 >;              /* in zephyr/dts/arm/st/h7/stm32h7.dtsi:1113 */
			#size-cells = < 0x0 >;                 /* in zephyr/dts/arm/st/h7/stm32h7.dtsi:1114 */
			reg = < 0x40015804 0x20 >;             /* in zephyr/dts/arm/st/h7/stm32h7.dtsi:1115 */
			clocks = < &rcc 0xf0 0x400000 >,
			         < &rcc 0xb 0x9c00050 >;       /* in zephyr/dts/arm/st/h7/stm32h7.dtsi:1116 */
			dmas = < &dma1 0x1 0x57 0x22800 0x0 >; /* in zephyr/dts/arm/st/h7/stm32h7.dtsi:1118 */
			status = "disabled";                   /* in zephyr/dts/arm/st/h7/stm32h7.dtsi:1120 */
		};

		/* node '/soc/sai1@40015824' defined in zephyr/dts/arm/st/h7/stm32h7.dtsi:1123 */
		sai1_b: sai1@40015824 {
			compatible = "st,stm32-sai";           /* in zephyr/dts/arm/st/h7/stm32h7.dtsi:1124 */
			#address-cells = < 0x1 >;              /* in zephyr/dts/arm/st/h7/stm32h7.dtsi:1125 */
			#size-cells = < 0x0 >;                 /* in zephyr/dts/arm/st/h7/stm32h7.dtsi:1126 */
			reg = < 0x40015824 0x20 >;             /* in zephyr/dts/arm/st/h7/stm32h7.dtsi:1127 */
			clocks = < &rcc 0xf0 0x400000 >,
			         < &rcc 0xb 0x9c00050 >;       /* in zephyr/dts/arm/st/h7/stm32h7.dtsi:1128 */
			dmas = < &dma1 0x0 0x58 0x22800 0x0 >; /* in zephyr/dts/arm/st/h7/stm32h7.dtsi:1130 */
			status = "disabled";                   /* in zephyr/dts/arm/st/h7/stm32h7.dtsi:1132 */
		};

		/* node '/soc/usb@40080000' defined in zephyr/dts/arm/st/h7/stm32h742.dtsi:32 */
		usbotg_fs: zephyr_udc0: usb@40080000 {
			compatible = "st,stm32-otgfs";                           /* in zephyr/dts/arm/st/h7/stm32h742.dtsi:33 */
			reg = < 0x40080000 0x40000 >;                            /* in zephyr/dts/arm/st/h7/stm32h742.dtsi:34 */
			interrupts = < 0x65 0x0 >,
			             < 0x62 0x0 >,
			             < 0x63 0x0 >;                               /* in zephyr/dts/arm/st/h7/stm32h742.dtsi:35 */
			interrupt-names = "otgfs",
			                  "ep1_out",
			                  "ep1_in";                              /* in zephyr/dts/arm/st/h7/stm32h742.dtsi:36 */
			num-bidir-endpoints = < 0x9 >;                           /* in zephyr/dts/arm/st/h7/stm32h742.dtsi:37 */
			ram-size = < 0x1000 >;                                   /* in zephyr/dts/arm/st/h7/stm32h742.dtsi:38 */
			maximum-speed = "full-speed";                            /* in zephyr/dts/arm/st/h7/stm32h742.dtsi:39 */
			clocks = < &rcc 0xd8 0x8000000 >,
			         < &rcc 0x5 0x18d40054 >;                        /* in zephyr/dts/arm/st/h7/stm32h742.dtsi:40 */
			phys = < &otghs_fs_phy >;                                /* in zephyr/dts/arm/st/h7/stm32h742.dtsi:42 */
			pinctrl-0 = < &usb_otg_fs_dm_pa11 &usb_otg_fs_dp_pa12 >; /* in zephyr/boards/st/nucleo_h753zi/nucleo_h753zi.dts:129 */
			pinctrl-names = "default";                               /* in zephyr/boards/st/nucleo_h753zi/nucleo_h753zi.dts:130 */
			status = "okay";                                         /* in zephyr/boards/st/nucleo_h753zi/nucleo_h753zi.dts:131 */
		};

		/* node '/soc/display-controller@50001000' defined in zephyr/dts/arm/st/h7/stm32h742.dtsi:46 */
		ltdc: display-controller@50001000 {
			compatible = "st,stm32-ltdc"; /* in zephyr/dts/arm/st/h7/stm32h742.dtsi:47 */
			reg = < 0x50001000 0x200 >;   /* in zephyr/dts/arm/st/h7/stm32h742.dtsi:48 */
			interrupts = < 0x58 0x0 >,
			             < 0x59 0x0 >;    /* in zephyr/dts/arm/st/h7/stm32h742.dtsi:49 */
			interrupt-names = "ltdc",
			                  "ltdc_er";  /* in zephyr/dts/arm/st/h7/stm32h742.dtsi:50 */
			clocks = < &rcc 0xe4 0x8 >;   /* in zephyr/dts/arm/st/h7/stm32h742.dtsi:51 */
			resets = < &rctl 0x1183 >;    /* in zephyr/dts/arm/st/h7/stm32h742.dtsi:52 */
			status = "disabled";          /* in zephyr/dts/arm/st/h7/stm32h742.dtsi:53 */
		};
	};

	/* node '/cpus' defined in zephyr/dts/arm/st/h7/stm32h7.dtsi:32 */
	cpus {
		#address-cells = < 0x1 >; /* in zephyr/dts/arm/st/h7/stm32h7.dtsi:33 */
		#size-cells = < 0x0 >;    /* in zephyr/dts/arm/st/h7/stm32h7.dtsi:34 */

		/* node '/cpus/cpu@0' defined in zephyr/dts/arm/st/h7/stm32h7.dtsi:36 */
		cpu0: cpu@0 {
			device_type = "cpu";          /* in zephyr/dts/arm/st/h7/stm32h7.dtsi:37 */
			compatible = "arm,cortex-m7"; /* in zephyr/dts/arm/st/h7/stm32h7.dtsi:38 */
			reg = < 0x0 >;                /* in zephyr/dts/arm/st/h7/stm32h7.dtsi:39 */
			#address-cells = < 0x1 >;     /* in zephyr/dts/arm/st/h7/stm32h7.dtsi:40 */
			#size-cells = < 0x1 >;        /* in zephyr/dts/arm/st/h7/stm32h7.dtsi:41 */

			/* node '/cpus/cpu@0/mpu@e000ed90' defined in zephyr/dts/arm/st/h7/stm32h7.dtsi:43 */
			mpu: mpu@e000ed90 {
				compatible = "arm,armv7m-mpu"; /* in zephyr/dts/arm/st/h7/stm32h7.dtsi:44 */
				reg = < 0xe000ed90 0x40 >;     /* in zephyr/dts/arm/st/h7/stm32h7.dtsi:45 */
			};
		};
	};

	/* node '/memory@90000000' defined in zephyr/dts/arm/st/h7/stm32h7.dtsi:50 */
	ext_memory: memory@90000000 {
		compatible = "zephyr,memory-region"; /* in zephyr/dts/arm/st/h7/stm32h7.dtsi:51 */
		reg = < 0x90000000 0x10000000 >;     /* in zephyr/dts/arm/st/h7/stm32h7.dtsi:52 */
		zephyr,memory-region = "EXTMEM";     /* in zephyr/dts/arm/st/h7/stm32h7.dtsi:53 */
		zephyr,memory-attr = < 0x2000000 >;  /* in zephyr/dts/arm/st/h7/stm32h7.dtsi:54 */
	};

	/* node '/clocks' defined in zephyr/dts/arm/st/h7/stm32h7.dtsi:57 */
	clocks {
		#address-cells = < 0x1 >; /* in zephyr/dts/arm/st/h7/stm32h7.dtsi:58 */
		#size-cells = < 0x0 >;    /* in zephyr/dts/arm/st/h7/stm32h7.dtsi:59 */

		/* node '/clocks/clk-hse' defined in zephyr/dts/arm/st/h7/stm32h7.dtsi:61 */
		clk_hse: clk-hse {
			#clock-cells = < 0x0 >;            /* in zephyr/dts/arm/st/h7/stm32h7.dtsi:62 */
			compatible = "st,stm32-hse-clock"; /* in zephyr/dts/arm/st/h7/stm32h7.dtsi:63 */
			hse-bypass;                        /* in zephyr/boards/st/nucleo_h753zi/nucleo_h753zi.dts:78 */
			clock-frequency = < 0x7a1200 >;    /* in zephyr/boards/st/nucleo_h753zi/nucleo_h753zi.dts:79 */
			status = "okay";                   /* in zephyr/boards/st/nucleo_h753zi/nucleo_h753zi.dts:80 */
			phandle = < 0x23 >;                /* in zephyr/boards/st/nucleo_h753zi/nucleo_h753zi.dts:89 */
		};

		/* node '/clocks/clk-hsi' defined in zephyr/dts/arm/st/h7/stm32h7.dtsi:67 */
		clk_hsi: clk-hsi {
			#clock-cells = < 0x0 >;              /* in zephyr/dts/arm/st/h7/stm32h7.dtsi:68 */
			compatible = "st,stm32h7-hsi-clock"; /* in zephyr/dts/arm/st/h7/stm32h7.dtsi:69 */
			hsi-div = < 0x1 >;                   /* in zephyr/dts/arm/st/h7/stm32h7.dtsi:70 */
			clock-frequency = < 0x3d09000 >;     /* in zephyr/dts/arm/st/h7/stm32h7.dtsi:71 */
			status = "disabled";                 /* in zephyr/dts/arm/st/h7/stm32h7.dtsi:72 */
		};

		/* node '/clocks/clk-hsi48' defined in zephyr/dts/arm/st/h7/stm32h7.dtsi:75 */
		clk_hsi48: clk-hsi48 {
			#clock-cells = < 0x0 >;          /* in zephyr/dts/arm/st/h7/stm32h7.dtsi:76 */
			compatible = "fixed-clock";      /* in zephyr/dts/arm/st/h7/stm32h7.dtsi:77 */
			clock-frequency = < 0x2dc6c00 >; /* in zephyr/dts/arm/st/h7/stm32h7.dtsi:78 */
			status = "okay";                 /* in zephyr/boards/st/nucleo_h753zi/nucleo_h753zi.dts:74 */
		};

		/* node '/clocks/clk-csi' defined in zephyr/dts/arm/st/h7/stm32h7.dtsi:82 */
		clk_csi: clk-csi {
			#clock-cells = < 0x0 >;         /* in zephyr/dts/arm/st/h7/stm32h7.dtsi:83 */
			compatible = "fixed-clock";     /* in zephyr/dts/arm/st/h7/stm32h7.dtsi:84 */
			clock-frequency = < 0x3d0900 >; /* in zephyr/dts/arm/st/h7/stm32h7.dtsi:85 */
			status = "disabled";            /* in zephyr/dts/arm/st/h7/stm32h7.dtsi:86 */
		};

		/* node '/clocks/clk-lse' defined in zephyr/dts/arm/st/h7/stm32h7.dtsi:89 */
		clk_lse: clk-lse {
			#clock-cells = < 0x0 >;            /* in zephyr/dts/arm/st/h7/stm32h7.dtsi:90 */
			compatible = "st,stm32-lse-clock"; /* in zephyr/dts/arm/st/h7/stm32h7.dtsi:91 */
			clock-frequency = < 0x8000 >;      /* in zephyr/dts/arm/st/h7/stm32h7.dtsi:92 */
			driving-capability = < 0x0 >;      /* in zephyr/dts/arm/st/h7/stm32h7.dtsi:93 */
			status = "disabled";               /* in zephyr/dts/arm/st/h7/stm32h7.dtsi:94 */
		};

		/* node '/clocks/clk-lsi' defined in zephyr/dts/arm/st/h7/stm32h7.dtsi:97 */
		clk_lsi: clk-lsi {
			#clock-cells = < 0x0 >;       /* in zephyr/dts/arm/st/h7/stm32h7.dtsi:98 */
			compatible = "fixed-clock";   /* in zephyr/dts/arm/st/h7/stm32h7.dtsi:99 */
			clock-frequency = < 0x7d00 >; /* in zephyr/dts/arm/st/h7/stm32h7.dtsi:100 */
			status = "okay";              /* in zephyr/boards/st/nucleo_h753zi/nucleo_h753zi.dts:70 */
		};

		/* node '/clocks/pll@0' defined in zephyr/dts/arm/st/h7/stm32h7.dtsi:104 */
		pll: pll@0 {
			#clock-cells = < 0x0 >;              /* in zephyr/dts/arm/st/h7/stm32h7.dtsi:105 */
			compatible = "st,stm32h7-pll-clock"; /* in zephyr/dts/arm/st/h7/stm32h7.dtsi:106 */
			reg = < 0x0 >;                       /* in zephyr/dts/arm/st/h7/stm32h7.dtsi:107 */
			div-m = < 0x2 >;                     /* in zephyr/boards/st/nucleo_h753zi/nucleo_h753zi.dts:84 */
			mul-n = < 0xf0 >;                    /* in zephyr/boards/st/nucleo_h753zi/nucleo_h753zi.dts:85 */
			div-p = < 0x2 >;                     /* in zephyr/boards/st/nucleo_h753zi/nucleo_h753zi.dts:86 */
			div-q = < 0x2 >;                     /* in zephyr/boards/st/nucleo_h753zi/nucleo_h753zi.dts:87 */
			div-r = < 0x2 >;                     /* in zephyr/boards/st/nucleo_h753zi/nucleo_h753zi.dts:88 */
			clocks = < &clk_hse >;               /* in zephyr/boards/st/nucleo_h753zi/nucleo_h753zi.dts:89 */
			status = "okay";                     /* in zephyr/boards/st/nucleo_h753zi/nucleo_h753zi.dts:90 */
			phandle = < 0x2 >;                   /* in zephyr/boards/st/nucleo_h753zi/nucleo_h753zi.dts:104 */
		};

		/* node '/clocks/pll@1' defined in zephyr/dts/arm/st/h7/stm32h7.dtsi:111 */
		pll2: pll@1 {
			#clock-cells = < 0x0 >;              /* in zephyr/dts/arm/st/h7/stm32h7.dtsi:112 */
			compatible = "st,stm32h7-pll-clock"; /* in zephyr/dts/arm/st/h7/stm32h7.dtsi:113 */
			reg = < 0x1 >;                       /* in zephyr/dts/arm/st/h7/stm32h7.dtsi:114 */
			div-m = < 0x4 >;                     /* in zephyr/boards/st/nucleo_h753zi/nucleo_h753zi.dts:94 */
			mul-n = < 0x78 >;                    /* in zephyr/boards/st/nucleo_h753zi/nucleo_h753zi.dts:95 */
			div-p = < 0x2 >;                     /* in zephyr/boards/st/nucleo_h753zi/nucleo_h753zi.dts:96 */
			div-q = < 0x3 >;                     /* in zephyr/boards/st/nucleo_h753zi/nucleo_h753zi.dts:97 */
			div-r = < 0x2 >;                     /* in zephyr/boards/st/nucleo_h753zi/nucleo_h753zi.dts:98 */
			clocks = < &clk_hse >;               /* in zephyr/boards/st/nucleo_h753zi/nucleo_h753zi.dts:99 */
			status = "okay";                     /* in zephyr/boards/st/nucleo_h753zi/nucleo_h753zi.dts:100 */
		};

		/* node '/clocks/pll@2' defined in zephyr/dts/arm/st/h7/stm32h7.dtsi:118 */
		pll3: pll@2 {
			#clock-cells = < 0x0 >;              /* in zephyr/dts/arm/st/h7/stm32h7.dtsi:119 */
			compatible = "st,stm32h7-pll-clock"; /* in zephyr/dts/arm/st/h7/stm32h7.dtsi:120 */
			reg = < 0x2 >;                       /* in zephyr/dts/arm/st/h7/stm32h7.dtsi:121 */
			status = "disabled";                 /* in zephyr/dts/arm/st/h7/stm32h7.dtsi:122 */
		};

		/* node '/clocks/perck' defined in zephyr/dts/arm/st/h7/stm32h7.dtsi:125 */
		perck: perck {
			#clock-cells = < 0x0 >;            /* in zephyr/dts/arm/st/h7/stm32h7.dtsi:126 */
			compatible = "st,stm32-clock-mux"; /* in zephyr/dts/arm/st/h7/stm32h7.dtsi:127 */
			status = "disabled";               /* in zephyr/dts/arm/st/h7/stm32h7.dtsi:128 */
		};
	};

	/* node '/mcos' defined in zephyr/dts/arm/st/h7/stm32h7.dtsi:132 */
	mcos {

		/* node '/mcos/mco1' defined in zephyr/dts/arm/st/h7/stm32h7.dtsi:133 */
		mco1: mco1 {
			compatible = "st,stm32-clock-mco"; /* in zephyr/dts/arm/st/h7/stm32h7.dtsi:134 */
			status = "disabled";               /* in zephyr/dts/arm/st/h7/stm32h7.dtsi:135 */
		};

		/* node '/mcos/mco2' defined in zephyr/dts/arm/st/h7/stm32h7.dtsi:138 */
		mco2: mco2 {
			compatible = "st,stm32-clock-mco"; /* in zephyr/dts/arm/st/h7/stm32h7.dtsi:139 */
			status = "disabled";               /* in zephyr/dts/arm/st/h7/stm32h7.dtsi:140 */
		};
	};

	/* node '/dietemp' defined in zephyr/dts/arm/st/h7/stm32h7.dtsi:1136 */
	die_temp: dietemp {
		compatible = "st,stm32-temp-cal"; /* in zephyr/dts/arm/st/h7/stm32h7.dtsi:1137 */
		ts-cal1-addr = < 0x1ff1e820 >;    /* in zephyr/dts/arm/st/h7/stm32h7.dtsi:1138 */
		ts-cal2-addr = < 0x1ff1e840 >;    /* in zephyr/dts/arm/st/h7/stm32h7.dtsi:1139 */
		ts-cal1-temp = < 0x1e >;          /* in zephyr/dts/arm/st/h7/stm32h7.dtsi:1140 */
		ts-cal2-temp = < 0x6e >;          /* in zephyr/dts/arm/st/h7/stm32h7.dtsi:1141 */
		ts-cal-vrefanalog = < 0xce4 >;    /* in zephyr/dts/arm/st/h7/stm32h7.dtsi:1142 */
		ts-cal-resolution = < 0x10 >;     /* in zephyr/dts/arm/st/h7/stm32h7.dtsi:1143 */
		io-channels = < &adc3 0x12 >;     /* in zephyr/dts/arm/st/h7/stm32h7.dtsi:1144 */
		status = "okay";                  /* in zephyr/boards/st/nucleo_h753zi/nucleo_h753zi.dts:175 */
	};

	/* node '/vbat' defined in zephyr/dts/arm/st/h7/stm32h7.dtsi:1148 */
	vbat: vbat {
		compatible = "st,stm32-vbat"; /* in zephyr/dts/arm/st/h7/stm32h7.dtsi:1149 */
		ratio = < 0x4 >;              /* in zephyr/dts/arm/st/h7/stm32h7.dtsi:1150 */
		status = "disabled";          /* in zephyr/dts/arm/st/h7/stm32h7.dtsi:1151 */
		io-channels = < &adc3 0x11 >; /* in zephyr/dts/arm/st/h7/stm32h742.dtsi:114 */
	};

	/* node '/vref' defined in zephyr/dts/arm/st/h7/stm32h7.dtsi:1154 */
	vref: vref {
		compatible = "st,stm32-vref";      /* in zephyr/dts/arm/st/h7/stm32h7.dtsi:1155 */
		vrefint-cal-addr = < 0x1ff1e860 >; /* in zephyr/dts/arm/st/h7/stm32h7.dtsi:1156 */
		vrefint-cal-mv = < 0xce4 >;        /* in zephyr/dts/arm/st/h7/stm32h7.dtsi:1157 */
		vrefint-cal-resolution = < 0x10 >; /* in zephyr/dts/arm/st/h7/stm32h7.dtsi:1158 */
		status = "disabled";               /* in zephyr/dts/arm/st/h7/stm32h7.dtsi:1159 */
		io-channels = < &adc3 0x13 >;      /* in zephyr/dts/arm/st/h7/stm32h742.dtsi:110 */
	};

	/* node '/smbus1' defined in zephyr/dts/arm/st/h7/stm32h7.dtsi:1162 */
	smbus1: smbus1 {
		compatible = "st,stm32-smbus"; /* in zephyr/dts/arm/st/h7/stm32h7.dtsi:1163 */
		#address-cells = < 0x1 >;      /* in zephyr/dts/arm/st/h7/stm32h7.dtsi:1164 */
		#size-cells = < 0x0 >;         /* in zephyr/dts/arm/st/h7/stm32h7.dtsi:1165 */
		i2c = < &i2c1 >;               /* in zephyr/dts/arm/st/h7/stm32h7.dtsi:1166 */
		status = "disabled";           /* in zephyr/dts/arm/st/h7/stm32h7.dtsi:1167 */
	};

	/* node '/smbus2' defined in zephyr/dts/arm/st/h7/stm32h7.dtsi:1170 */
	smbus2: smbus2 {
		compatible = "st,stm32-smbus"; /* in zephyr/dts/arm/st/h7/stm32h7.dtsi:1171 */
		#address-cells = < 0x1 >;      /* in zephyr/dts/arm/st/h7/stm32h7.dtsi:1172 */
		#size-cells = < 0x0 >;         /* in zephyr/dts/arm/st/h7/stm32h7.dtsi:1173 */
		i2c = < &i2c2 >;               /* in zephyr/dts/arm/st/h7/stm32h7.dtsi:1174 */
		status = "disabled";           /* in zephyr/dts/arm/st/h7/stm32h7.dtsi:1175 */
	};

	/* node '/smbus3' defined in zephyr/dts/arm/st/h7/stm32h7.dtsi:1178 */
	smbus3: smbus3 {
		compatible = "st,stm32-smbus"; /* in zephyr/dts/arm/st/h7/stm32h7.dtsi:1179 */
		#address-cells = < 0x1 >;      /* in zephyr/dts/arm/st/h7/stm32h7.dtsi:1180 */
		#size-cells = < 0x0 >;         /* in zephyr/dts/arm/st/h7/stm32h7.dtsi:1181 */
		i2c = < &i2c3 >;               /* in zephyr/dts/arm/st/h7/stm32h7.dtsi:1182 */
		status = "disabled";           /* in zephyr/dts/arm/st/h7/stm32h7.dtsi:1183 */
	};

	/* node '/smbus4' defined in zephyr/dts/arm/st/h7/stm32h7.dtsi:1186 */
	smbus4: smbus4 {
		compatible = "st,stm32-smbus"; /* in zephyr/dts/arm/st/h7/stm32h7.dtsi:1187 */
		#address-cells = < 0x1 >;      /* in zephyr/dts/arm/st/h7/stm32h7.dtsi:1188 */
		#size-cells = < 0x0 >;         /* in zephyr/dts/arm/st/h7/stm32h7.dtsi:1189 */
		i2c = < &i2c4 >;               /* in zephyr/dts/arm/st/h7/stm32h7.dtsi:1190 */
		status = "disabled";           /* in zephyr/dts/arm/st/h7/stm32h7.dtsi:1191 */
	};

	/* node '/memory@24000000' defined in zephyr/dts/arm/st/h7/stm32h742.dtsi:66 */
	sram0: memory@24000000 {
		compatible = "mmio-sram";     /* in zephyr/dts/arm/st/h7/stm32h742.dtsi:67 */
		reg = < 0x24000000 0x80000 >; /* in zephyr/dts/arm/st/h7/stm32h743.dtsi:17 */
	};

	/* node '/memory@30000000' defined in zephyr/dts/arm/st/h7/stm32h742.dtsi:72 */
	sram1: memory@30000000 {
		compatible = "zephyr,memory-region",
		             "mmio-sram";            /* in zephyr/dts/arm/st/h7/stm32h742.dtsi:73 */
		zephyr,memory-region = "SRAM1";      /* in zephyr/dts/arm/st/h7/stm32h742.dtsi:75 */
		reg = < 0x30000000 0x20000 >;        /* in zephyr/dts/arm/st/h7/stm32h743.dtsi:22 */
	};

	/* node '/memory@30020000' defined in zephyr/dts/arm/st/h7/stm32h742.dtsi:79 */
	sram2: memory@30020000 {
		compatible = "zephyr,memory-region",
		             "mmio-sram";            /* in zephyr/dts/arm/st/h7/stm32h742.dtsi:80 */
		zephyr,memory-region = "SRAM2";      /* in zephyr/dts/arm/st/h7/stm32h742.dtsi:82 */
		reg = < 0x30020000 0x20000 >;        /* in zephyr/dts/arm/st/h7/stm32h743.dtsi:27 */
	};

	/* node '/memory@38000000' defined in zephyr/dts/arm/st/h7/stm32h742.dtsi:86 */
	sram4: memory@38000000 {
		compatible = "zephyr,memory-region",
		             "mmio-sram";            /* in zephyr/dts/arm/st/h7/stm32h742.dtsi:87 */
		reg = < 0x38000000 0x10000 >;        /* in zephyr/dts/arm/st/h7/stm32h742.dtsi:88 */
		zephyr,memory-region = "SRAM4";      /* in zephyr/dts/arm/st/h7/stm32h742.dtsi:89 */
	};

	/* node '/memory@20000000' defined in zephyr/dts/arm/st/h7/stm32h742.dtsi:92 */
	dtcm: memory@20000000 {
		compatible = "zephyr,memory-region",
		             "arm,dtcm";             /* in zephyr/dts/arm/st/h7/stm32h742.dtsi:93 */
		reg = < 0x20000000 0x20000 >;        /* in zephyr/dts/arm/st/h7/stm32h742.dtsi:94 */
		zephyr,memory-region = "DTCM";       /* in zephyr/dts/arm/st/h7/stm32h742.dtsi:95 */
	};

	/* node '/memory@0' defined in zephyr/dts/arm/st/h7/stm32h742.dtsi:98 */
	itcm: memory@0 {
		compatible = "zephyr,memory-region",
		             "arm,itcm";             /* in zephyr/dts/arm/st/h7/stm32h742.dtsi:99 */
		reg = < 0x0 0x10000 >;               /* in zephyr/dts/arm/st/h7/stm32h742.dtsi:100 */
		zephyr,memory-region = "ITCM";       /* in zephyr/dts/arm/st/h7/stm32h742.dtsi:101 */
	};

	/* node '/otghs_fs_phy' defined in zephyr/dts/arm/st/h7/stm32h742.dtsi:104 */
	otghs_fs_phy: otghs_fs_phy {
		compatible = "usb-nop-xceiv"; /* in zephyr/dts/arm/st/h7/stm32h742.dtsi:105 */
		#phy-cells = < 0x0 >;         /* in zephyr/dts/arm/st/h7/stm32h742.dtsi:106 */
		phandle = < 0x20 >;           /* in zephyr/dts/arm/st/h7/stm32h742.dtsi:42 */
	};

	/* node '/memory@30040000' defined in zephyr/dts/arm/st/h7/stm32h743.dtsi:31 */
	sram3: memory@30040000 {
		compatible = "zephyr,memory-region",
		             "mmio-sram";            /* in zephyr/dts/arm/st/h7/stm32h743.dtsi:32 */
		reg = < 0x30040000 0x8000 >;         /* in zephyr/dts/arm/st/h7/stm32h743.dtsi:33 */
		zephyr,memory-region = "SRAM3";      /* in zephyr/dts/arm/st/h7/stm32h743.dtsi:34 */
	};

	/* node '/connector' defined in zephyr/boards/st/nucleo_h753zi/arduino_r3_connector.dtsi:8 */
	arduino_header: connector {
		compatible = "arduino-header-r3";          /* in zephyr/boards/st/nucleo_h753zi/arduino_r3_connector.dtsi:9 */
		#gpio-cells = < 0x2 >;                     /* in zephyr/boards/st/nucleo_h753zi/arduino_r3_connector.dtsi:10 */
		gpio-map-mask = < 0xffffffff 0xffffffc0 >; /* in zephyr/boards/st/nucleo_h753zi/arduino_r3_connector.dtsi:11 */
		gpio-map-pass-thru = < 0x0 0x3f >;         /* in zephyr/boards/st/nucleo_h753zi/arduino_r3_connector.dtsi:12 */
		gpio-map = < 0x0 0x0 &gpioa 0x3 0x0 >,
		           < 0x1 0x0 &gpioc 0x0 0x0 >,
		           < 0x2 0x0 &gpioc 0x3 0x0 >,
		           < 0x3 0x0 &gpiob 0x1 0x0 >,
		           < 0x4 0x0 &gpioc 0x2 0x0 >,
		           < 0x5 0x0 &gpiof 0xa 0x0 >,
		           < 0x6 0x0 &gpiob 0x7 0x0 >,
		           < 0x7 0x0 &gpiob 0x6 0x0 >,
		           < 0x8 0x0 &gpiog 0xe 0x0 >,
		           < 0x9 0x0 &gpioe 0xd 0x0 >,
		           < 0xa 0x0 &gpioe 0xe 0x0 >,
		           < 0xb 0x0 &gpioe 0xb 0x0 >,
		           < 0xc 0x0 &gpioe 0x9 0x0 >,
		           < 0xd 0x0 &gpiog 0xc 0x0 >,
		           < 0xe 0x0 &gpiof 0x3 0x0 >,
		           < 0xf 0x0 &gpiod 0xf 0x0 >,
		           < 0x10 0x0 &gpiod 0xe 0x0 >,
		           < 0x11 0x0 &gpiob 0x5 0x0 >,
		           < 0x12 0x0 &gpioa 0x6 0x0 >,
		           < 0x13 0x0 &gpioa 0x5 0x0 >,
		           < 0x14 0x0 &gpiob 0x9 0x0 >,
		           < 0x15 0x0 &gpiob 0x8 0x0 >;    /* in zephyr/boards/st/nucleo_h753zi/arduino_r3_connector.dtsi:13 */
	};

	/* node '/leds' defined in zephyr/boards/st/nucleo_h753zi/nucleo_h753zi.dts:27 */
	leds: leds {
		compatible = "gpio-leds"; /* in zephyr/boards/st/nucleo_h753zi/nucleo_h753zi.dts:28 */

		/* node '/leds/led_0' defined in zephyr/boards/st/nucleo_h753zi/nucleo_h753zi.dts:30 */
		green_led: led_0 {
			gpios = < &gpiob 0x0 0x0 >; /* in zephyr/boards/st/nucleo_h753zi/nucleo_h753zi.dts:31 */
			label = "User LD1";         /* in zephyr/boards/st/nucleo_h753zi/nucleo_h753zi.dts:32 */
		};

		/* node '/leds/led_1' defined in zephyr/boards/st/nucleo_h753zi/nucleo_h753zi.dts:35 */
		yellow_led: led_1 {
			gpios = < &gpioe 0x1 0x0 >; /* in zephyr/boards/st/nucleo_h753zi/nucleo_h753zi.dts:36 */
			label = "User LD2";         /* in zephyr/boards/st/nucleo_h753zi/nucleo_h753zi.dts:37 */
		};
	};

	/* node '/pwmleds' defined in zephyr/boards/st/nucleo_h753zi/nucleo_h753zi.dts:41 */
	pwmleds {
		compatible = "pwm-leds"; /* in zephyr/boards/st/nucleo_h753zi/nucleo_h753zi.dts:42 */

		/* node '/pwmleds/red_pwm_led' defined in zephyr/boards/st/nucleo_h753zi/nucleo_h753zi.dts:44 */
		red_pwm_led: red_pwm_led {
			pwms = < &pwm12 0x1 0x1312d00 0x0 >; /* in zephyr/boards/st/nucleo_h753zi/nucleo_h753zi.dts:45 */
		};
	};

	/* node '/gpio_keys' defined in zephyr/boards/st/nucleo_h753zi/nucleo_h753zi.dts:49 */
	gpio_keys {
		compatible = "gpio-keys"; /* in zephyr/boards/st/nucleo_h753zi/nucleo_h753zi.dts:50 */

		/* node '/gpio_keys/button_0' defined in zephyr/boards/st/nucleo_h753zi/nucleo_h753zi.dts:52 */
		user_button: button_0 {
			label = "User";             /* in zephyr/boards/st/nucleo_h753zi/nucleo_h753zi.dts:53 */
			gpios = < &gpioc 0xd 0x0 >; /* in zephyr/boards/st/nucleo_h753zi/nucleo_h753zi.dts:54 */
			zephyr,code = < 0xb >;      /* in zephyr/boards/st/nucleo_h753zi/nucleo_h753zi.dts:55 */
		};
	};

	/* node '/ihm02a1-cs' defined in ../apps/stm32h753zi_stepper/boards/shields/x_nucleo_ihm02a1/x_nucleo_ihm02a1.overlay:49 */
	ihm02a1_cs: ihm02a1-cs {
		gpios = < &gpiod 0xe 0x1 >; /* in ../apps/stm32h753zi_stepper/boards/shields/x_nucleo_ihm02a1/x_nucleo_ihm02a1.overlay:50 */
		status = "okay";            /* in ../apps/stm32h753zi_stepper/boards/shields/x_nucleo_ihm02a1/x_nucleo_ihm02a1.overlay:51 */
	};

	/* node '/ihm02a1-flag' defined in ../apps/stm32h753zi_stepper/boards/shields/x_nucleo_ihm02a1/x_nucleo_ihm02a1.overlay:54 */
	ihm02a1_flag: ihm02a1-flag {
		gpios = < &gpiog 0xe 0x1 >; /* in ../apps/stm32h753zi_stepper/boards/shields/x_nucleo_ihm02a1/x_nucleo_ihm02a1.overlay:55 */
		status = "okay";            /* in ../apps/stm32h753zi_stepper/boards/shields/x_nucleo_ihm02a1/x_nucleo_ihm02a1.overlay:56 */
	};

	/* node '/ihm02a1-busy' defined in ../apps/stm32h753zi_stepper/boards/shields/x_nucleo_ihm02a1/x_nucleo_ihm02a1.overlay:59 */
	ihm02a1_busy: ihm02a1-busy {
		gpios = < &gpioe 0xd 0x0 >; /* in ../apps/stm32h753zi_stepper/boards/shields/x_nucleo_ihm02a1/x_nucleo_ihm02a1.overlay:60 */
		status = "okay";            /* in ../apps/stm32h753zi_stepper/boards/shields/x_nucleo_ihm02a1/x_nucleo_ihm02a1.overlay:61 */
	};

	/* node '/ihm02a1-reset' defined in ../apps/stm32h753zi_stepper/boards/shields/x_nucleo_ihm02a1/x_nucleo_ihm02a1.overlay:64 */
	ihm02a1_reset: ihm02a1-reset {
		gpios = < &gpioe 0xe 0x1 >; /* in ../apps/stm32h753zi_stepper/boards/shields/x_nucleo_ihm02a1/x_nucleo_ihm02a1.overlay:65 */
		status = "okay";            /* in ../apps/stm32h753zi_stepper/boards/shields/x_nucleo_ihm02a1/x_nucleo_ihm02a1.overlay:66 */
	};
};
